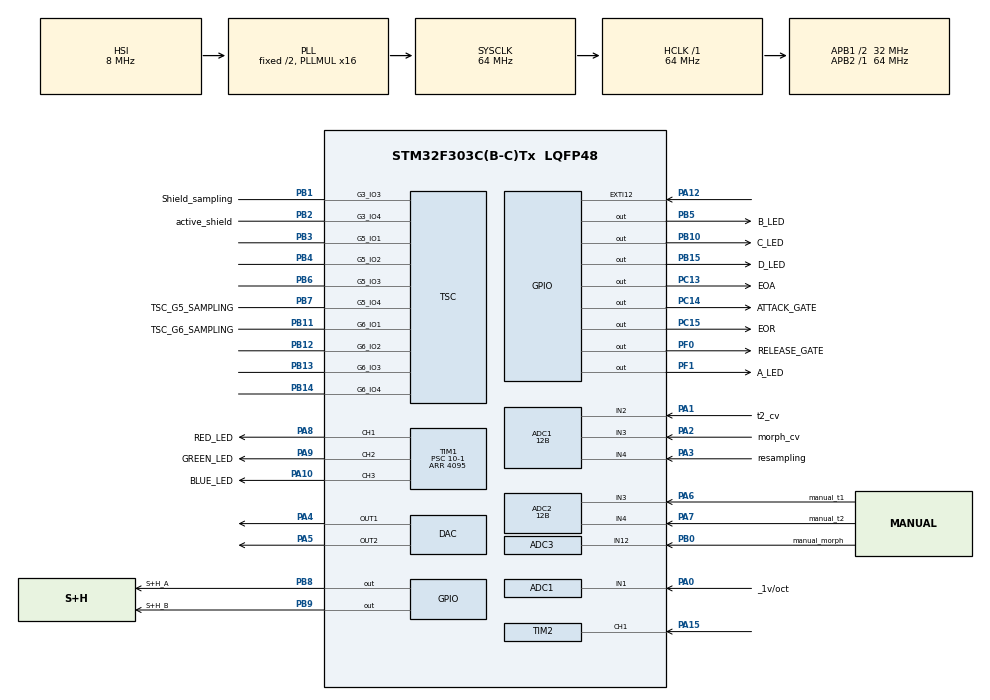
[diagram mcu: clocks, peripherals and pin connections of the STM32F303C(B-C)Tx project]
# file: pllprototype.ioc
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ADC1.Channel-0\#ChannelRegularConversion=ADC_CHANNEL_1
ADC1.Channel-1\#ChannelRegularConversion=ADC_CHANNEL_2
ADC1.Channel-2\#ChannelRegularConversion=ADC_CHANNEL_3
ADC1.Channel-4\#ChannelRegularConversion=ADC_CHANNEL_4
ADC1.ClockPrescaler=ADC_CLOCK_ASYNC_DIV1
ADC1.ContinuousConvMode=ENABLE
ADC1.DMAContinuousRequests=ENABLE
ADC1.DataAlign=ADC_DATAALIGN_RIGHT
ADC1.DiscontinuousConvMode=DISABLE
ADC1.EOCSelection=ADC_EOC_SEQ_CONV
ADC1.EnableAnalogWatchDog1=false
ADC1.EnableAnalogWatchDog2=false
ADC1.EnableAnalogWatchDog3=false
ADC1.EnableInjectedConversion=DISABLE
ADC1.EnableRegularConversion=ENABLE
ADC1.ExternalTrigConv=ADC_SOFTWARE_START
ADC1.ExternalTrigConvEdge=ADC_EXTERNALTRIGCONVEDGE_NONE
ADC1.LowPowerAutoWait=DISABLE
ADC1.NbrOfConversion=4
ADC1.NbrOfConversionFlag=1
ADC1.Offset-0\#ChannelRegularConversion=0
ADC1.Offset-1\#ChannelRegularConversion=0
ADC1.Offset-2\#ChannelRegularConversion=0
ADC1.Offset-4\#ChannelRegularConversion=0
ADC1.OffsetNumber-0\#ChannelRegularConversion=ADC_OFFSET_NONE
ADC1.OffsetNumber-1\#ChannelRegularConversion=ADC_OFFSET_NONE
ADC1.OffsetNumber-2\#ChannelRegularConversion=ADC_OFFSET_NONE
ADC1.OffsetNumber-4\#ChannelRegularConversion=ADC_OFFSET_NONE
ADC1.Overrun=ADC_OVR_DATA_OVERWRITTEN
ADC1.Rank-0\#ChannelRegularConversion=1
ADC1.Rank-1\#ChannelRegularConversion=2
ADC1.Rank-2\#ChannelRegularConversion=3
ADC1.Rank-4\#ChannelRegularConversion=4
ADC1.Resolution=ADC_RESOLUTION_12B
ADC1.SamplingTime-0\#ChannelRegularConversion=ADC_SAMPLETIME_181CYCLES_5
ADC1.SamplingTime-1\#ChannelRegularConversion=ADC_SAMPLETIME_181CYCLES_5
ADC1.SamplingTime-2\#ChannelRegularConversion=ADC_SAMPLETIME_181CYCLES_5
ADC1.SamplingTime-4\#ChannelRegularConversion=ADC_SAMPLETIME_181CYCLES_5
ADC1.ScanConvMode=ADC_SCAN_ENABLE
ADC1.master=1
ADC2.Channel-0\#ChannelRegularConversion=ADC_CHANNEL_3
ADC2.Channel-1\#ChannelRegularConversion=ADC_CHANNEL_4
ADC2.ClockPrescaler=ADC_CLOCK_ASYNC_DIV1
ADC2.ContinuousConvMode=ENABLE
ADC2.DMAContinuousRequests=ENABLE
ADC2.DataAlign=ADC_DATAALIGN_RIGHT
ADC2.DiscontinuousConvMode=DISABLE
ADC2.EOCSelection=ADC_EOC_SEQ_CONV
ADC2.EnableAnalogWatchDog1=false
ADC2.EnableAnalogWatchDog2=false
ADC2.EnableAnalogWatchDog3=false
ADC2.EnableInjectedConversion=ENABLE
ADC2.EnableRegularConversion=ENABLE
ADC2.ExternalTrigConv=ADC_SOFTWARE_START
ADC2.ExternalTrigConvEdge=ADC_EXTERNALTRIGCONVEDGE_NONE
ADC2.InjNumberOfConversion=0
ADC2.LowPowerAutoWait=DISABLE
ADC2.NbrOfConversion=2
ADC2.NbrOfConversionFlag=1
ADC2.Offset-0\#ChannelRegularConversion=0
ADC2.Offset-1\#ChannelRegularConversion=0
ADC2.OffsetNumber-0\#ChannelRegularConversion=ADC_OFFSET_NONE
ADC2.OffsetNumber-1\#ChannelRegularConversion=ADC_OFFSET_1
ADC2.Overrun=ADC_OVR_DATA_OVERWRITTEN
ADC2.Rank-0\#ChannelRegularConversion=1
ADC2.Rank-1\#ChannelRegularConversion=2
ADC2.Resolution=ADC_RESOLUTION_12B
ADC2.SamplingTime-0\#ChannelRegularConversion=ADC_SAMPLETIME_61CYCLES_5
ADC2.SamplingTime-1\#ChannelRegularConversion=ADC_SAMPLETIME_61CYCLES_5
ADC2.ScanConvMode=ADC_SCAN_ENABLE
ADC3.Channel-106\#ChannelRegularConversion=ADC_CHANNEL_12
ADC3.ClockPrescaler=ADC_CLOCK_ASYNC_DIV1
ADC3.ContinuousConvMode=ENABLE
ADC3.DMAContinuousRequests=ENABLE
ADC3.DataAlign=ADC_DATAALIGN_RIGHT
ADC3.DiscontinuousConvMode=DISABLE
ADC3.EOCSelection=ADC_EOC_SINGLE_CONV
ADC3.EnableAnalogWatchDog1=false
ADC3.EnableAnalogWatchDog2=false
ADC3.EnableAnalogWatchDog3=false
ADC3.EnableInjectedConversion=DISABLE
ADC3.EnableRegularConversion=ENABLE
ADC3.ExternalTrigConv=ADC_SOFTWARE_START
ADC3.ExternalTrigConvEdge=ADC_EXTERNALTRIGCONVEDGE_NONE
ADC3.LowPowerAutoWait=DISABLE
ADC3.NbrOfConversion=1
ADC3.NbrOfConversionFlag=1
ADC3.Offset-106\#ChannelRegularConversion=0
ADC3.OffsetNumber-106\#ChannelRegularConversion=ADC_OFFSET_NONE
ADC3.Overrun=ADC_OVR_DATA_OVERWRITTEN
ADC3.Rank-106\#ChannelRegularConversion=1
ADC3.Resolution=ADC_RESOLUTION_12B
ADC3.SamplingTime-106\#ChannelRegularConversion=ADC_SAMPLETIME_61CYCLES_5
ADC3.ScanConvMode=ADC_SCAN_DISABLE
ADC3.master=1
DAC.DAC_OutputBuffer=DAC_OUTPUTBUFFER_DISABLE
DAC.DAC_OutputBuffer2=DAC_OUTPUTBUFFER_DISABLE
DAC.DAC_Trigger=DAC_TRIGGER_T6_TRGO
DAC.DAC_Trigger2=DAC_TRIGGER_T6_TRGO
Dma.ADC1.0.Direction=DMA_PERIPH_TO_MEMORY
Dma.ADC1.0.Instance=DMA1_Channel1
Dma.ADC1.0.MemDataAlignment=DMA_MDATAALIGN_WORD
Dma.ADC1.0.MemInc=DMA_MINC_ENABLE
Dma.ADC1.0.Mode=DMA_CIRCULAR
Dma.ADC1.0.PeriphDataAlignment=DMA_PDATAALIGN_WORD
Dma.ADC1.0.PeriphInc=DMA_PINC_DISABLE
Dma.ADC1.0.Priority=DMA_PRIORITY_LOW
Dma.ADC2.1.Direction=DMA_PERIPH_TO_MEMORY
Dma.ADC2.1.Instance=DMA2_Channel1
Dma.ADC2.1.MemDataAlignment=DMA_MDATAALIGN_WORD
Dma.ADC2.1.MemInc=DMA_MINC_ENABLE
Dma.ADC2.1.Mode=DMA_CIRCULAR
Dma.ADC2.1.PeriphDataAlignment=DMA_PDATAALIGN_WORD
Dma.ADC2.1.PeriphInc=DMA_PINC_DISABLE
Dma.ADC2.1.Priority=DMA_PRIORITY_HIGH
Dma.ADC3.2.Direction=DMA_PERIPH_TO_MEMORY
Dma.ADC3.2.Instance=DMA2_Channel5
Dma.ADC3.2.MemDataAlignment=DMA_MDATAALIGN_WORD
Dma.ADC3.2.MemInc=DMA_MINC_ENABLE
Dma.ADC3.2.Mode=DMA_CIRCULAR
Dma.ADC3.2.PeriphDataAlignment=DMA_PDATAALIGN_WORD
Dma.ADC3.2.PeriphInc=DMA_PINC_DISABLE
Dma.ADC3.2.Priority=DMA_PRIORITY_HIGH
Dma.DAC_CH1.3.Direction=DMA_MEMORY_TO_PERIPH
Dma.DAC_CH1.3.Instance=DMA1_Channel3
Dma.DAC_CH1.3.MemDataAlignment=DMA_MDATAALIGN_HALFWORD
Dma.DAC_CH1.3.MemInc=DMA_MINC_ENABLE
Dma.DAC_CH1.3.Mode=DMA_CIRCULAR
Dma.DAC_CH1.3.PeriphDataAlignment=DMA_PDATAALIGN_HALFWORD
Dma.DAC_CH1.3.PeriphInc=DMA_PINC_DISABLE
Dma.DAC_CH1.3.Priority=DMA_PRIORITY_VERY_HIGH
Dma.DAC_CH2.4.Direction=DMA_MEMORY_TO_PERIPH
Dma.DAC_CH2.4.Instance=DMA1_Channel4
Dma.DAC_CH2.4.MemDataAlignment=DMA_MDATAALIGN_HALFWORD
Dma.DAC_CH2.4.MemInc=DMA_MINC_ENABLE
Dma.DAC_CH2.4.Mode=DMA_CIRCULAR
Dma.DAC_CH2.4.PeriphDataAlignment=DMA_PDATAALIGN_HALFWORD
Dma.DAC_CH2.4.PeriphInc=DMA_PINC_DISABLE
Dma.DAC_CH2.4.Priority=DMA_PRIORITY_VERY_HIGH
Dma.Request0=ADC1
Dma.Request1=ADC2
Dma.Request2=ADC3
Dma.Request3=DAC_CH1
Dma.Request4=DAC_CH2
Mcu.Family=STM32F3
Mcu.Name=STM32F303C(B-C)Tx
Mcu.Package=LQFP48
NVIC.DMA1_Channel1_IRQn=true\:2\:1\:true\:false\:true
NVIC.DMA1_Channel3_IRQn=true\:0\:0\:true\:false\:true
NVIC.DMA1_Channel4_IRQn=true\:0\:0\:true\:false\:true
NVIC.DMA2_Channel1_IRQn=true\:3\:0\:true\:false\:true
NVIC.DMA2_Channel5_IRQn=true\:2\:0\:true\:false\:true
NVIC.EXTI15_10_IRQn=true\:1\:0\:true\:false\:true
NVIC.PriorityGroup=NVIC_PRIORITYGROUP_2
NVIC.TIM2_IRQn=true\:0\:0\:false\:false\:true
NVIC.TIM6_DAC_IRQn=true\:0\:2\:false\:false\:true
NVIC.TIM7_IRQn=true\:0\:1\:false\:false\:true
NVIC.TIM8_UP_IRQn=true\:0\:1\:false\:false\:true
PA0.GPIO_Label=_1v/oct
PA0.Mode=IN1-Single-Ended
PA0.Signal=ADC1_IN1
PA1.GPIO_Label=t2_cv
PA1.Mode=IN2-Single-Ended
PA1.Signal=ADC1_IN2
PA10.GPIO_Label=BLUE_LED
PA10.Signal=S_TIM1_CH3
PA12.Signal=GPXTI12
PA13.Signal=SYS_JTMS-SWDIO
PA14.Signal=SYS_JTCK-SWCLK
PA15.Signal=S_TIM2_CH1_ETR
PA2.GPIO_Label=morph_cv
PA2.Mode=IN3-Single-Ended
PA2.Signal=ADC1_IN3
PA3.GPIO_Label=resampling
PA3.Mode=IN4-Single-Ended
PA3.Signal=ADC1_IN4
PA4.GPIO_Mode=GPIO_MODE_ANALOG
PA4.Signal=COMP_DAC1_group
PA5.Signal=COMP_DAC2_group
PA6.GPIO_Label=manual_t1
PA6.Mode=IN3-Single-Ended
PA6.Signal=ADC2_IN3
PA7.GPIO_Label=manual_t2
PA7.Mode=IN4-Single-Ended
PA7.Signal=ADC2_IN4
PA8.GPIO_Label=RED_LED
PA8.Signal=S_TIM1_CH1
PA9.GPIO_Label=GREEN_LED
PA9.Signal=S_TIM1_CH2
PB0.GPIO_Label=manual_morph
PB0.Mode=IN12-Single-Ended
PB0.Signal=ADC3_IN12
PB1.GPIO_Label=Shield_sampling
PB1.Mode=G3_IO3-Sampling
PB1.Signal=TSC_G3_IO3
PB10.GPIO_Label=C_LED
PB10.Signal=GPIO_Output
PB11.GPIO_Label=TSC_G6_SAMPLING
PB11.Mode=G6_IO1-Sampling
PB11.Signal=TSC_G6_IO1
PB12.Mode=G6_IO2-Channel
PB12.Signal=TSC_G6_IO2
PB13.Mode=G6_IO3-Channel
PB13.Signal=TSC_G6_IO3
PB14.Mode=G6_IO4-Channel
PB14.Signal=TSC_G6_IO4
PB15.GPIO_Label=D_LED
PB15.Signal=GPIO_Output
PB2.GPIO_Label=active_shield
PB2.Mode=G3_IO4-Shield
PB2.Signal=TSC_G3_IO4
PB3.Mode=G5_IO1-Channel
PB3.Signal=TSC_G5_IO1
PB4.Mode=G5_IO2-Channel
PB4.Signal=TSC_G5_IO2
PB5.GPIO_Label=B_LED
PB5.Signal=GPIO_Output
PB6.Mode=G5_IO3-Channel
PB6.Signal=TSC_G5_IO3
PB7.GPIO_Label=TSC_G5_SAMPLING
PB7.Mode=G5_IO4-Sampling
PB7.Signal=TSC_G5_IO4
PB8.GPIO_Label=S+H_A
PB8.Signal=GPIO_Output
PB9.GPIO_Label=S+H_B
PB9.Signal=GPIO_Output
PC13.GPIO_Label=EOA
PC13.Signal=GPIO_Output
PC14-OSC32_IN.GPIO_Label=ATTACK_GATE
PC14-OSC32_IN.Signal=GPIO_Output
PC15-OSC32_OUT.GPIO_Label=EOR
PC15-OSC32_OUT.Signal=GPIO_Output
PF0-OSC_IN.GPIO_Label=RELEASE_GATE
PF0-OSC_IN.Signal=GPIO_Output
PF1-OSC_OUT.GPIO_Label=A_LED
PF1-OSC_OUT.Signal=GPIO_Output
ProjectManager.HeapSize=0x200
ProjectManager.StackSize=0x400
ProjectManager.TargetToolchain=SW4STM32
RCC.ADC12PRES=RCC_ADC12PLLCLK_DIV16
RCC.ADC34PRES=RCC_ADC34PLLCLK_DIV16
RCC.AHBFreq_Value=64000000
RCC.APB1CLKDivider=RCC_HCLK_DIV2
RCC.APB1Freq_Value=32000000
RCC.APB1TimFreq_Value=64000000
RCC.APB2Freq_Value=64000000
RCC.APB2TimFreq_Value=64000000
RCC.CortexFreq_Value=64000000
RCC.HCLKFreq_Value=64000000
RCC.HSE_VALUE=8000000
RCC.HSI_VALUE=8000000
RCC.LSE_VALUE=32768
RCC.PLLMUL=RCC_PLL_MUL16
RCC.SYSCLKFreq_VALUE=64000000
RCC.SYSCLKSourceVirtual=RCC_SYSCLKSOURCE_PLLCLK
RCC.USBFreq_Value=64000000
SH.COMP_DAC1_group.0=DAC_OUT1,DAC_OUT1
SH.COMP_DAC2_group.0=DAC_OUT2,Enable_DAC_OUT2
SH.S_TIM1_CH1.0=TIM1_CH1,PWM Generation1 CH1
SH.S_TIM1_CH2.0=TIM1_CH2,PWM Generation2 CH2
SH.S_TIM1_CH3.0=TIM1_CH3,PWM Generation3 CH3
SH.S_TIM2_CH1_ETR.0=TIM2_CH1,Input_Capture1_from_TI1
TIM1.Channel-PWM\ Generation1\ CH1=TIM_CHANNEL_1
TIM1.Channel-PWM\ Generation2\ CH2=TIM_CHANNEL_2
TIM1.Channel-PWM\ Generation3\ CH3=TIM_CHANNEL_3
TIM1.Period=4095
TIM1.Prescaler=10-1
TIM2.Channel-Input_Capture1_from_TI1=TIM_CHANNEL_1
TIM2.ICPolarity_CH1=TIM_INPUTCHANNELPOLARITY_BOTHEDGE
TIM2.Period=4294967295
TIM2.Prescaler=1024
TIM4.Period=60000
TIM4.Prescaler=10000
TIM6.Period=1000
TIM6.Prescaler=1-1
TIM6.TIM_MasterOutputTrigger=TIM_TRGO_UPDATE
TIM7.Period=65535
TIM7.Prescaler=1-1
TIM8.Period=65535
TIM8.Prescaler=1-1
TIM8.RepetitionCounter=0
TIM8.TIM_MasterOutputTrigger=TIM_TRGO_UPDATE
TSC.CTPulseHighLength=TSC_CTPH_2CYCLES
TSC.CTPulseLowLength=TSC_CTPL_9CYCLES
TSC.ChannelIOs-G5_IO1=TSC_GROUP5_IO1
TSC.ChannelIOs-G5_IO2=TSC_GROUP5_IO2
TSC.ChannelIOs-G5_IO3=TSC_GROUP5_IO3
TSC.ChannelIOs-G6_IO2=TSC_GROUP6_IO2
TSC.ChannelIOs-G6_IO3=TSC_GROUP6_IO3
TSC.ChannelIOs-G6_IO4=TSC_GROUP6_IO4
TSC.MaxCountValue=TSC_MCV_16383
TSC.PulseGeneratorPrescaler=TSC_PG_PRESC_DIV32
TSC.SamplingIOs-G3_IO3=TSC_GROUP3_IO3
TSC.SamplingIOs-G5_IO4=TSC_GROUP5_IO4
TSC.SamplingIOs-G6_IO1=TSC_GROUP6_IO1
TSC.ShieldIOs-G3_IO4=TSC_GROUP3_IO4
VP_TIM3_VS_ClockSourceINT.Mode=Internal
VP_TIM4_VS_ClockSourceINT.Mode=Internal
VP_TIM6_VS_ClockSourceINT.Mode=Enable_Timer
VP_TIM7_VS_ClockSourceINT.Mode=Enable_Timer
VP_TIM8_VS_ClockSourceINT.Mode=Internal
board=pllprototype

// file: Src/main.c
/**
  ******************************************************************************
  * File Name          : main.c
  * Description        : Main program body
  ******************************************************************************
  ** This notice applies to any and all portions of this file
  * that are not between comment pairs USER CODE BEGIN and
  * USER CODE END. Other portions of this file, whether
  * inserted by the user or by software development tools
  * are owned by their respective copyright owners.
  *
  * COPYRIGHT(c) 2017 STMicroelectronics
  *
  * Redistribution and use in source and binary forms, with or without modification,
  * are permitted provided that the following conditions are met:
  *   1. Redistributions of source code must retain the above copyright notice,
  *      this list of conditions and the following disclaimer.
  *   2. Redistributions in binary form must reproduce the above copyright notice,
  *      this list of conditions and the following disclaimer in the documentation
  *      and/or other materials provided with the distribution.
  *   3. Neither the name of STMicroelectronics nor the names of its contributors
  *      may be used to endorse or promote products derived from this software
  *      without specific prior written permission.
  *
  * THIS SOFTWARE IS PROVIDED BY THE COPYRIGHT HOLDERS AND CONTRIBUTORS "AS IS"
  * AND ANY EXPRESS OR IMPLIED WARRANTIES, INCLUDING, BUT NOT LIMITED TO, THE
  * IMPLIED WARRANTIES OF MERCHANTABILITY AND FITNESS FOR A PARTICULAR PURPOSE ARE
  * DISCLAIMED. IN NO EVENT SHALL THE COPYRIGHT HOLDER OR CONTRIBUTORS BE LIABLE
  * FOR ANY DIRECT, INDIRECT, INCIDENTAL, SPECIAL, EXEMPLARY, OR CONSEQUENTIAL
  * DAMAGES (INCLUDING, BUT NOT LIMITED TO, PROCUREMENT OF SUBSTITUTE GOODS OR
  * SERVICES; LOSS OF USE, DATA, OR PROFITS; OR BUSINESS INTERRUPTION) HOWEVER
  * CAUSED AND ON ANY THEORY OF LIABILITY, WHETHER IN CONTRACT, STRICT LIABILITY,
  * OR TORT (INCLUDING NEGLIGENCE OR OTHERWISE) ARISING IN ANY WAY OUT OF THE USE
  * OF THIS SOFTWARE, EVEN IF ADVISED OF THE POSSIBILITY OF SUCH DAMAGE.
  *
  ******************************************************************************
  */
#include "main.h"
#include "stm32f3xx_hal.h"

/* USER CODE BEGIN Includes */

#include "tables.h"
#include "tsl_user.h"

/* USER CODE END Includes */

ADC_HandleTypeDef hadc1;
ADC_HandleTypeDef hadc2;
ADC_HandleTypeDef hadc3;
DMA_HandleTypeDef hdma_adc1;
DMA_HandleTypeDef hdma_adc2;
DMA_HandleTypeDef hdma_adc3;

DAC_HandleTypeDef hdac;
DMA_HandleTypeDef hdma_dac_ch1;
DMA_HandleTypeDef hdma_dac_ch2;

TIM_HandleTypeDef htim1;
TIM_HandleTypeDef htim2;
TIM_HandleTypeDef htim3;
TIM_HandleTypeDef htim4;
TIM_HandleTypeDef htim6;
TIM_HandleTypeDef htim7;
TIM_HandleTypeDef htim8;

TSC_HandleTypeDef htsc;

/* USER CODE BEGIN PV */
/* Private variables ---------------------------------------------------------*/
tsl_user_status_t tsl_status;

__IO uint32_t uhTSCAcquisitionValue1;
__IO uint32_t uhTSCAcquisitionValue2;
__IO uint32_t uhTSCAcquisitionValue3;
uint8_t not1;
uint8_t not2;
uint8_t not3;
uint8_t modeflag;
uint8_t modechanged;
uint8_t displayNewMode;
extern uint8_t morphBitShiftRight;
extern uint8_t morphBitShiftLeft;
extern uint8_t rowSelectBitShift;
extern uint8_t rowIndexBitShift;
uint8_t detectOn;
uint8_t rgbOn;
extern uint16_t dacbuffer1[1];
extern uint16_t dacbuffer2[1];
extern int span;
extern int spanx2;

Scale ratio1;
Scale row1;

Family moog1;
Family moog2;
Family triFudge;
Family triOdd;
Family triFold;
Family bounce;
Family sineFold;
Family perlin;
Family sawBend;
Family exciteBike;
Family rand;
Family gauss;
Family gauss_noconform;
Family gauss_low;
Family gauss_low_noconform;
Family algerian;
Family gammaSym;
Family gammaAsym;
Family sharpExpoSym;
Family sharpExpoAsym;
Family sharpLinSym;
Family sharpLinAsym;
Family quartSym;
Family quartAsym;
Family superEllipse1Sym;
Family superEllipse1Asym;
Family moogShifted;

const uint16_t sinefold_ctr_1[65] = {0,1755,3221,4645,6025,7357,8637,9863,11031,12137,13180,14156,15062,15896,16655,17337,17940,18463,18903,19259,19530,19715,19812,19822,19745,19579,19325,18984,18556,18042,17444,16762,15997,15259,14604,14034,13550,13154,12845,12624,12492,12448,12493,12624,12843,13148,13537,14009,14563,15197,15909,16696,17557,18488,19487,20551,21677,22863,24104,25398,26741,28130,29561,31030,32768};
const uint16_t sinefold_ctr_2[65] = {0,735,1259,1832,2482,3231,4097,5090,6218,7480,8869,10372,11969,13636,15341,17052,18730,20335,21825,23161,24303,25213,25859,26213,26252,25964,25339,24379,23093,21501,19628,17509,15187,12963,10988,9296,7917,6870,6166,5806,5785,6088,6693,7574,8696,10023,11515,13131,14828,16565,18303,20007,21645,23190,24621,25924,27091,28119,29012,29783,30447,31025,31543,32030,32768};
const uint16_t sinefold_ctr_3[65] = {0,1698,2972,4008,4759,5208,5364,5267,4983,4601,4226,3968,3938,4234,4933,6083,7697,9753,12185,14894,17747,20586,23240,25535,27307,28412,28742,28231,26863,24677,21768,18281,14409,10771,7722,5412,3942,3356,3639,4728,6512,8846,11561,14478,17418,20219,22740,24873,26549,27737,28448,28727,28651,28318,27841,27335,26911,26662,26663,26961,27572,28483,29656,31026,32768};
const uint16_t sinefold_ctr_4[65] = {0,827,1647,2786,4263,6018,7918,9775,11374,12512,13030,12844,11969,10523,8724,6864,5274,4281,4160,5092,7127,10171,13982,18193,22350,25964,28571,29796,29408,27353,23780,19032,13614,8672,4934,2756,2299,3514,6166,9871,14153,18505,22452,25608,27717,28670,28514,27428,25695,23655,21655,20007,18947,18612,19030,20124,21737,23660,25668,27557,29175,30442,31360,32006,32768};
const uint16_t sinefold_ctr_5[65] = {0,1576,2476,2878,2871,2694,2678,3159,4381,6420,9135,12181,15062,17239,18250,17829,15991,13057,9621,6444,4306,3841,5390,8900,13903,19579,24897,28810,30469,29407,25662,19805,12856,6767,2848,1696,3360,7368,12845,18710,23890,27526,29122,28610,26333,22945,19260,16080,14038,13488,14462,16696,19711,22937,25840,28032,29339,29815,29699,29340,29097,29247,29920,31077,32768};
const uint16_t sinefold_ctr_6[65] = {0,977,2212,3929,5831,7442,8290,8112,6998,5417,4099,3814,5096,8024,12132,16485,19931,21445,20475,17162,12380,7530,4166,3534,6163,11644,18681,25400,29868,30658,27309,20531,12068,5026,1515,2280,6858,13784,21058,26733,29449,28766,25218,20093,15011,11449,10339,11855,15433,20004,24346,27453,28799,28436,26914,25047,23638,23227,23960,25598,27651,29594,31059,31964,32768};
const uint16_t sinefold_ctr_7[65] = {0,1403,1889,1892,1985,2828,4785,7645,10624,12658,12901,11177,8184,5312,4112,5618,9820,15529,20752,23450,22400,17800,11328,5581,3088,5257,11703,20262,27730,31090,28747,21273,11321,3559,1087,4514,12206,21050,27721,29956,27333,21299,14479,9592,8413,11176,16624,22618,27044,28617,27287,24128,20787,18775,18889,20990,24192,27338,29519,30429,30392,30108,30246,31109,32768};
const uint16_t sinefold_ctr_8[65] = {0,1183,2787,4626,5846,5807,4645,3364,3333,5433,9376,13652,16226,15679,12144,7468,4397,5132,10028,17171,23183,24917,21207,13688,6178,2812,5853,14324,24276,30659,29922,21997,10574,2346,1533,8091,18364,27125,30263,26737,18873,10971,7023,8770,15021,22496,27632,28380,25071,20011,16123,15415,18087,22653,26917,29192,29085,27501,25944,25602,26747,28760,30686,31907,32768};
const uint16_t sinefold_ctr_9[65] = {0,1208,1408,1616,2871,5455,8387,9978,9130,6420,4019,4332,8189,13940,18250,18266,13738,7559,4126,6444,13876,22185,26075,22715,13903,5260,2754,8701,19910,29407,30828,22720,9847,1428,2848,12632,24214,30362,27737,18710,9474,5901,9905,18561,26333,28746,25082,18474,13573,13488,18015,24142,28274,28564,25840,22689,21546,23154,26386,29340,30779,30849,30655,31193,32768};

const uint16_t perlin6_1[65] = {0,506,1016,1530,2048,2571,3098,3630,4167,4710,5257,5809,6366,6928,7494,8065,8640,9220,9803,10389,10933,11475,12016,12554,13089,13621,14150,14676,15197,15715,16231,16744,17256,17766,18275,18781,19286,19789,20290,20789,21287,21783,22277,22770,23261,23750,24182,24615,25048,25482,25917,26354,26792,27232,27675,28119,28567,29017,29470,29926,30386,30850,31317,31788,32768};
const uint16_t perlin6_2[65] = {0,509,1030,1565,2116,2686,3276,3889,4524,5184,5869,6581,7318,8081,8870,9683,10520,11380,12259,13157,13870,14574,15268,15949,16614,17263,17893,18501,19087,19648,20197,20734,21260,21776,22280,22773,23255,23726,24187,24636,25075,25504,25921,26329,26726,27113,27263,27418,27580,27749,27928,28118,28320,28537,28770,29020,29288,29577,29887,30220,30576,30958,31366,31801,32768};
const uint16_t perlin6_3[65] = {0,637,1150,1548,1842,2049,2186,2275,2335,2390,2463,2576,2753,3013,3377,3863,4484,5252,6175,7256,8573,9949,11363,12796,14225,15624,16967,18225,19367,20374,21300,22158,22947,23670,24327,24920,25450,25919,26331,26687,26992,27249,27461,27633,27769,27874,27703,27559,27450,27383,27364,27399,27490,27640,27850,28120,28447,28827,29255,29724,30223,30741,31263,31774,32768};
const uint16_t perlin6_4[65] = {0,1104,2256,3414,4530,5550,6422,7101,7551,7753,7706,7435,6969,6171,5095,3860,2598,1447,539,0,442,1391,2821,4676,6872,9297,11811,14244,16402,18109,19518,20675,21586,22265,22729,23001,23109,23084,22963,22788,22606,22466,22427,22548,22894,23537,24453,25507,26569,27550,28392,29063,29553,29874,30049,30115,30113,30092,30097,30171,30346,30647,31079,31626,32768};
const uint16_t perlin6_5[65] = {0,499,902,1384,2080,3062,4289,5573,6561,7774,9487,11465,13433,15108,16235,16623,16181,14956,13166,10795,7881,5388,3857,3617,4786,7268,10755,14729,18458,21149,23030,24234,24826,24907,24614,24122,23639,23410,23718,24874,26758,28827,30689,32061,32768,32748,31582,30074,28532,27293,26472,25874,25616,25740,26216,26966,27871,28806,29654,30328,30774,31024,31290,31695,32768};
const uint16_t perlin6_6[65] = {0,788,1427,2217,3244,4395,5371,5701,4859,3531,2511,2335,3263,5117,7114,8212,10359,13034,15132,15838,14533,11966,8845,5193,2606,2214,4304,8321,12867,15992,17702,18286,18014,17297,16689,16888,18578,20974,22948,23838,23423,21917,19975,18425,17110,16425,16970,18312,20051,21630,22324,21970,21562,21703,22599,24151,26062,27964,29499,30411,30778,30879,31047,31515,32768};
const uint16_t perlin6_7[65] = {0,937,1522,2229,4238,7257,9498,9498,7319,5535,6018,7917,9727,9496,5678,2034,1274,3929,8008,10336,14681,17905,17712,14140,8920,3467,1989,5823,12719,17537,19360,19052,17779,17313,19715,23299,25128,24154,21193,18510,16540,16233,17764,20098,20845,18603,16927,17695,20985,25530,29335,30539,29242,27090,26102,24823,24498,25688,27786,29618,30428,30697,30966,31532,32768};
const uint16_t perlin6_8[65] = {0,732,1600,2059,1672,2325,5490,7424,6651,5814,9852,16521,17502,11423,7005,8782,11929,10370,2717,0,5062,10222,15607,19933,17642,10620,2893,3240,11926,18684,20047,18398,17675,21936,25633,24350,19955,16641,15944,18468,20719,17637,15180,17907,25024,31174,30392,25532,22472,19214,20437,25394,28710,28524,27257,27795,29755,30221,29518,29293,30185,30903,31182,31418,32768};
const uint16_t perlin6_9[65] = {0,891,1396,1274,1955,3741,4554,4824,5999,4396,3821,8798,9933,7145,10625,18843,15572,7019,8364,11363,5181,821,6172,10989,16882,15319,7315,2095,9076,16039,16248,14467,17988,21186,17975,13935,13044,15952,15240,12004,15182,22729,24628,19481,15160,12879,18936,23570,22479,21810,25200,25563,23796,24810,26072,25319,22196,22622,27131,30539,30446,29524,29958,31137,32768};

const uint16_t bounce1[65] = {0,543,1136,1766,2419,3082,3741,4384,4999,5575,6099,6564,6962,7284,7526,7684,7756,7741,7640,7455,7190,6852,6447,5984,5473,4923,4348,3759,3170,2594,2044,1536,1081,694,387,172,60,60,181,429,811,1329,1985,2780,3710,4773,5962,7269,8685,10197,11793,13457,15174,16925,18692,20455,22194,23888,25516,27058,28492,29799,30959,31954,32768};
const uint16_t bounce2[65] = {0,554,1157,1774,2369,2910,3371,3732,3980,4111,4130,4049,3891,3681,3454,3245,3090,3026,3086,3297,3680,4246,4999,5929,7018,8238,9549,10907,12259,13551,14725,15728,16509,17025,17241,17136,16701,15940,14874,13538,11981,10263,8456,6639,4896,3311,1967,940,297,91,361,1126,2388,4127,6303,8857,11710,14772,17936,21091,24121,26908,29343,31325,32768};
const uint16_t bounce3[65] = {0,570,1185,1769,2260,2611,2800,2833,2742,2581,2419,2334,2400,2677,3203,3988,5009,6212,7511,8803,9970,10897,11482,11650,11360,10616,9469,8013,6382,4738,3256,2112,1458,1416,2055,3386,5360,7859,10715,13714,16619,19185,21187,22436,22803,22230,20740,18440,15514,12208,8816,5651,3020,1196,393,745,2287,4956,8585,12917,17625,22337,26667,30249,32768};
const uint16_t bounce4[65] = {0,589,1204,1721,2054,2173,2109,1953,1831,1878,2204,2869,3861,5093,6408,7610,8492,8883,8678,7873,6568,4969,3352,2031,1299,1377,2374,4252,6828,9788,12727,15217,16867,17393,16673,14772,11949,8624,5323,2599,947,721,2075,4922,8941,13610,18284,22283,24999,25997,25081,22347,18169,13160,8088,3758,898,36,1418,4957,10233,16548,23018,28709,32768};
const uint16_t bounce5[65] = {0,610,1212,1629,1777,1698,1539,1510,1805,2529,3647,4976,6225,7068,7246,6649,5376,3731,2164,1166,1137,2272,4482,7394,10413,12861,14137,13881,12086,9124,5685,2630,792,763,2738,6436,11142,15851,19496,21205,20517,17524,12871,7638,3097,418,390,3204,8390,14889,21288,26132,28273,27153,22961,16619,9592,3563,45,16,3670,10343,18637,26726,32768};
const uint16_t bounce6[65] = {0,631,1204,1500,1485,1331,1336,1768,2722,4037,5330,6131,6082,5114,3524,1914,994,1319,3052,5850,8934,11323,12178,11121,8419,4952,1954,603,1603,4891,9605,14320,17506,18052,15680,11098,5815,1677,250,2265,7325,13973,20134,23790,23666,19705,13143,6157,1165,24,3378,10382,18931,26309,30085,28937,23146,14559,6030,501,16,5004,14080,24443,32768};
const uint16_t bounce7[65] = {0,651,1184,1353,1236,1184,1590,2606,3982,5145,5489,4736,3170,1583,939,1882,4349,7496,10016,10732,9201,6018,2639,777,1593,5094,10021,14330,16091,14408,9917,4608,995,987,4959,11476,17842,21263,20125,14810,7630,1874,363,4129,11855,20357,25945,26076,20564,11773,3655,31,2850,11231,21744,29860,31954,26977,17029,6526,295,1412,9754,21947,32768};
const uint16_t bounce8[65] = {0,650,1114,1164,1040,1255,2141,3492,4601,4719,3638,1980,928,1510,3857,6959,9141,9061,6615,3175,910,1520,5127,10027,13555,13618,10029,4785,1051,1344,5968,12666,17778,18333,13859,6837,1413,1042,6408,14852,21751,23140,18074,9351,2053,680,6482,16570,25418,27974,22636,12337,3027,325,6230,17813,28726,32768,27499,15799,4383,44,5702,18583,31630};
const uint16_t bounce9[65] = {0,640,1024,974,937,1514,2762,3963,4150,3015,1392,780,2174,5098,7715,8103,5800,2406,609,2218,6638,11042,12296,9328,4155,657,1810,7364,13754,16501,13490,6726,1145,1151,7317,15703,20484,18130,10149,2271,471,6597,16789,24013,23047,14395,4197,10,5355,16969,26879,28009,19372,7038,9,3792,16260,28903,32768,24934,10853,694,2141,14740,29954};

const uint16_t trifold_1[65] = {0,512,1024,1536,2048,2560,3072,3584,4096,4608,5120,5632,6144,6656,7168,7680,8192,8704,9216,9728,10240,10752,11264,11776,12288,12800,13312,13824,14336,14848,15360,15872,16384,16896,17408,17920,18432,18944,19456,19968,20480,20992,21504,22016,22528,23040,23552,24064,24576,25088,25600,26112,26624,27136,27648,28160,28672,29184,29696,30208,30720,31232,31744,32256,32768};
const uint16_t trifold_2[65] = {32768,31232,29696,28160,26624,25088,23552,22016,20480,18944,17408,15872,14336,12800,11264,9728,8192,6656,5120,3584,2048,512,0,1536,3072,4608,6144,7680,9216,10752,12288,13824,15360,16896,18432,19968,21504,23040,24576,26112,27648,29184,30720,32256,31744,30208,28672,27136,25600,24064,22528,20992,19456,17920,16384,14848,13312,11776,10240,8704,7168,5632,4096,2560,1024};
const uint16_t trifold_3[65] = {16384,18432,20480,22528,24576,26624,28672,30720,32768,31232,29184,27136,25088,23040,20992,18944,16896,14848,12800,10752,8704,6656,4608,2560,512,1024,3072,5120,7168,9216,11264,13312,15360,17408,19456,21504,23552,25600,27648,29696,31744,32256,30208,28160,26112,24064,22016,19968,17920,15872,13824,11776,9728,7680,5632,3584,1536,0,2048,4096,6144,8192,10240,12288,14336};
const uint16_t trifold_4[65] = {0,2521,5041,7562,10082,12603,15124,17644,20165,22686,25206,27727,30247,32768,30247,27727,25206,22686,20165,17644,15124,12603,10082,7562,5041,2521,0,2521,5041,7562,10082,12603,15124,17644,20165,22686,25206,27727,30247,32768,30247,27727,25206,22686,20165,17644,15124,12603,10082,7562,5041,2521,0,2521,5041,7562,10082,12603,15124,17644,20165,22686,25206,27727,30247};
const uint16_t trifold_5[65] = {16384,13312,10240,7168,4096,1024,1536,4608,7680,10752,13824,16896,19968,23040,26112,29184,32256,30720,27648,24576,21504,18432,15360,12288,9216,6144,3072,0,2560,5632,8704,11776,14848,17920,20992,24064,27136,30208,32768,29696,26624,23552,20480,17408,14336,11264,8192,5120,2048,512,3584,6656,9728,12800,15872,18944,22016,25088,28160,31232,31744,28672,25600,22528,19456};
const uint16_t trifold_6[65] = {32768,29184,25600,22016,18432,14848,11264,7680,4096,512,2048,5632,9216,12800,16384,19968,23552,27136,30720,31232,27648,24064,20480,16896,13312,9728,6144,2560,0,3584,7168,10752,14336,17920,21504,25088,28672,32256,29696,26112,22528,18944,15360,11776,8192,4608,1024,1536,5120,8704,12288,15872,19456,23040,26624,30208,31744,28160,24576,20992,17408,13824,10240,6656,3072};
const uint16_t trifold_7[65] = {16384,20480,24576,28672,32768,29184,25088,20992,16896,12800,8704,4608,512,3072,7168,11264,15360,19456,23552,27648,31744,30208,26112,22016,17920,13824,9728,5632,1536,2048,6144,10240,14336,18432,22528,26624,30720,31232,27136,23040,18944,14848,10752,6656,2560,1024,5120,9216,13312,17408,21504,25600,29696,32256,28160,24064,19968,15872,11776,7680,3584,0,4096,8192,12288};
const uint16_t trifold_8[65] = {0,4608,9216,13824,18432,23040,27648,32256,29696,25088,20480,15872,11264,6656,2048,2560,7168,11776,16384,20992,25600,30208,31744,27136,22528,17920,13312,8704,4096,512,5120,9728,14336,18944,23552,28160,32768,29184,24576,19968,15360,10752,6144,1536,3072,7680,12288,16896,21504,26112,30720,31232,26624,22016,17408,12800,8192,3584,1024,5632,10240,14848,19456,24064,28672};
const uint16_t trifold_9[65] = {16384,10923,5461,0,2731,8192,13653,19115,24576,30037,32768,27307,21845,16384,10923,5461,0,2731,8192,13653,19115,24576,30037,32768,27307,21845,16384,10923,5461,0,2731,8192,13653,19115,24576,30037,32768,27307,21845,16384,10923,5461,0,2731,8192,13653,19115,24576,30037,32768,27307,21845,16384,10923,5461,0,2731,8192,13653,19115,24576,30037,32768,27307,21845};

const uint16_t triodd_1[65] = {0,512,1024,1536,2048,2560,3072,3584,4096,4608,5120,5632,6144,6656,7168,7680,8192,8704,9216,9728,10240,10752,11264,11776,12288,12800,13312,13824,14336,14848,15360,15872,16384,16896,17408,17920,18432,18944,19456,19968,20480,20992,21504,22016,22528,23040,23552,24064,24576,25088,25600,26112,26624,27136,27648,28160,28672,29184,29696,30208,30720,31232,31744,32256,32768};
const uint16_t triodd_2[65] = {1024,2560,4096,5632,7168,8704,10240,11776,13312,14848,16384,17920,19456,20992,22528,24064,25600,27136,28672,30208,31744,32256,30720,29184,27648,26112,24576,23040,21504,19968,18432,16896,15360,13824,12288,10752,9216,7680,6144,4608,3072,1536,0,512,2048,3584,5120,6656,8192,9728,11264,12800,14336,15872,17408,18944,20480,22016,23552,25088,26624,28160,29696,31232,32768};
const uint16_t triodd_3[65] = {0,2521,5041,7562,10082,12603,15124,17644,20165,22686,25206,27727,30247,32768,30247,27727,25206,22686,20165,17644,15124,12603,10082,7562,5041,2521,0,2521,5041,7562,10082,12603,15124,17644,20165,22686,25206,27727,30247,32768,30247,27727,25206,22686,20165,17644,15124,12603,10082,7562,5041,2521,0,2521,5041,7562,10082,12603,15124,17644,20165,22686,25206,27727,30247};
const uint16_t triodd_4[65] = {3072,6656,10240,13824,17408,20992,24576,28160,31744,30208,26624,23040,19456,15872,12288,8704,5120,1536,1024,4608,8192,11776,15360,18944,22528,26112,29696,32256,28672,25088,21504,17920,14336,10752,7168,3584,0,2560,6144,9728,13312,16896,20480,24064,27648,31232,30720,27136,23552,19968,16384,12800,9216,5632,2048,512,4096,7680,11264,14848,18432,22016,25600,29184,32768};
const uint16_t triodd_5[65] = {0,4608,9216,13824,18432,23040,27648,32256,29696,25088,20480,15872,11264,6656,2048,2560,7168,11776,16384,20992,25600,30208,31744,27136,22528,17920,13312,8704,4096,512,5120,9728,14336,18944,23552,28160,32768,29184,24576,19968,15360,10752,6144,1536,3072,7680,12288,16896,21504,26112,30720,31232,26624,22016,17408,12800,8192,3584,1024,5632,10240,14848,19456,24064,28672};
const uint16_t triodd_6[65] = {5120,10752,16384,22016,27648,32256,26624,20992,15360,9728,4096,512,6144,11776,17408,23040,28672,31232,25600,19968,14336,8704,3072,1536,7168,12800,18432,24064,29696,30208,24576,18944,13312,7680,2048,2560,8192,13824,19456,25088,30720,29184,23552,17920,12288,6656,1024,3584,9216,14848,20480,26112,31744,28160,22528,16896,11264,5632,0,4608,10240,15872,21504,27136,32768};
const uint16_t triodd_7[65] = {0,6554,13107,19661,26214,32768,26214,19661,13107,6554,0,6554,13107,19661,26214,32768,26214,19661,13107,6554,0,6554,13107,19661,26214,32768,26214,19661,13107,6554,0,6554,13107,19661,26214,32768,26214,19661,13107,6554,0,6554,13107,19661,26214,32768,26214,19661,13107,6554,0,6554,13107,19661,26214,32768,26214,19661,13107,6554,0,6554,13107,19661,26214};
const uint16_t triodd_8[65] = {7562,15124,22686,30247,27727,20165,12603,5041,2521,10082,17644,25206,32768,25206,17644,10082,2521,5041,12603,20165,27727,30247,22686,15124,7562,0,7562,15124,22686,30247,27727,20165,12603,5041,2521,10082,17644,25206,32768,25206,17644,10082,2521,5041,12603,20165,27727,30247,22686,15124,7562,0,7562,15124,22686,30247,27727,20165,12603,5041,2521,10082,17644,25206,32768};
const uint16_t triodd_9[65] = {0,8704,17408,26112,31744,23040,14336,5632,3072,11776,20480,29184,28672,19968,11264,2560,6144,14848,23552,32256,25600,16896,8192,512,9216,17920,26624,31232,22528,13824,5120,3584,12288,20992,29696,28160,19456,10752,2048,6656,15360,24064,32768,25088,16384,7680,1024,9728,18432,27136,30720,22016,13312,4608,4096,12800,21504,30208,27648,18944,10240,1536,7168,15872,24576};

const uint16_t trifudge_1[65] = {256,752,1248,1744,2240,2736,3232,3728,4224,4720,5216,5712,6208,6704,7200,7696,8192,8704,9216,9728,10240,10752,11264,11776,12288,12800,13312,13824,14336,14848,15360,15872,16384,16896,17408,17920,18432,18944,19456,19968,20480,20992,21504,22016,22528,23040,23552,24064,24576,25104,25632,26160,26688,27216,27744,28272,28800,29328,29856,30384,30912,31440,31968,32496,32512};
const uint16_t trifudge_2[65] = {0,1632,3328,5088,6912,8800,10752,12768,14848,16992,19200,21472,23808,26208,28672,31200,32256,31232,30208,29184,28160,27136,26112,25088,24064,23040,22016,20992,19968,18944,17920,16896,15872,14848,13824,12800,11776,10752,9728,8704,7680,6656,5632,4608,3584,2560,1536,512,0,2528,4992,7392,9728,12000,14208,16352,18432,20448,22400,24288,26112,27872,29568,31200,32768};
const uint16_t trifudge_3[65] = {1024,2560,4096,5632,7168,8704,10240,11776,13312,14848,16384,17920,19456,20992,22528,24064,25600,27136,28672,30208,31744,32256,30720,29184,27648,26112,24576,23040,21504,19968,18432,16896,15360,13824,12288,10752,9216,7680,6144,4608,3072,1536,0,512,2048,3584,5120,6656,8192,9728,11264,12800,14336,15872,17408,18944,20480,22016,23552,25088,26624,28160,29696,31232,32768};
const uint16_t trifudge_4[65] = {0,3072,6583,10533,14921,19749,25015,30720,32768,31232,29184,27136,25088,23040,20992,18944,16896,14848,12800,10752,8704,6656,4608,2560,512,1024,3072,5120,7168,9216,11264,13312,15360,17408,19456,21504,23552,25600,27648,29696,31744,32256,30208,28160,26112,24064,22016,19968,17920,15872,13824,11776,9728,7680,5632,3584,1536,0,5998,11557,16677,21358,25600,29403,32768};
const uint16_t trifudge_5[65] = {0,2521,5041,7562,10082,12603,15124,17644,20165,22686,25206,27727,30247,32768,30247,27727,25206,22686,20165,17644,15124,12603,10082,7562,5041,2521,0,2521,5041,7562,10082,12603,15124,17644,20165,22686,25206,27727,30247,32768,30247,27727,25206,22686,20165,17644,15124,12603,10082,7562,5041,2521,0,2521,5041,7562,10082,12603,15124,17644,20165,22686,25206,27727,30247};
const uint16_t trifudge_6[65] = {0,6016,13312,21888,31744,31232,28160,25088,22016,18944,15872,12800,9728,6656,3584,512,2048,5120,8192,11264,14336,17408,20480,23552,26624,29696,32768,30208,27136,24064,20992,17920,14848,11776,8704,5632,2560,0,3072,6144,9216,12288,15360,18432,21504,24576,27648,30720,32256,29184,26112,23040,19968,16896,13824,10752,7680,4608,1536,1024,4096,13184,20992,27520,32768};
const uint16_t trifudge_7[65] = {3072,6656,10240,13824,17408,20992,24576,28160,31744,30208,26624,23040,19456,15872,12288,8704,5120,1536,1024,4608,8192,11776,15360,18944,22528,26112,29696,32256,28672,25088,21504,17920,14336,10752,7168,3584,0,2560,6144,9728,13312,16896,20480,24064,27648,31232,30720,27136,23552,19968,16384,12800,9216,5632,2048,512,4096,7680,11264,14848,18432,22016,25600,29184,32768};
const uint16_t trifudge_8[65] = {0,7168,16725,28672,32768,29184,25088,20992,16896,12800,8704,4608,512,3072,7168,11264,15360,19456,23552,27648,31744,30208,26112,22016,17920,13824,9728,5632,1536,2048,6144,10240,14336,18432,22528,26624,30720,31232,27136,23040,18944,14848,10752,6656,2560,1024,5120,9216,13312,17408,21504,25600,29696,32256,28160,24064,19968,15872,11776,7680,3584,0,13312,24235,32768};
const uint16_t trifudge_9[65] = {0,4608,9216,13824,18432,23040,27648,32256,29696,25088,20480,15872,11264,6656,2048,2560,7168,11776,16384,20992,25600,30208,31744,27136,22528,17920,13312,8704,4096,512,5120,9728,14336,18944,23552,28160,32768,29184,24576,19968,15360,10752,6144,1536,3072,7680,12288,16896,21504,26112,30720,31232,26624,22016,17408,12800,8192,3584,1024,5632,10240,14848,19456,24064,28672};

const uint16_t moog1attack[65] = { 21659 ,  21503 ,  20634 ,  18818 ,  16219 ,  13251 ,  10408 ,   8124 , 6692 ,   6231 ,   6690 ,   7878 ,   9512 ,  11283 ,12902 ,  14146 , 14884 ,  15086 ,  14809 ,  14180 ,  13364 ,  12531 ,  11830 ,  11367 , 11196 ,  11315 ,  11676 ,  12202 ,  12798 ,  13372 ,  13850 ,  14183 , 14352 ,  14367 ,  14262 ,  14084 ,  13886 ,  13715 ,  13609 ,  13588 , 13658 ,  13807 ,  14014 ,  14251 ,  14490 ,  14705 ,  14880 ,  15005 , 15082 ,  15119 ,  15129 ,  15128 ,  15131 ,  15151 ,  15195 ,  15267 , 15365 ,  15483 ,  15612 ,  15745 ,  15872 ,  15988 ,  16090 ,  16177 , 16251 };
const uint16_t moog1release[65] = { 21602 ,  21529 ,  21444 ,  21360 ,  21275 ,  21190 ,  21105 ,  21020 , 20934 ,  20849 ,  20764 ,  20679 ,  20594 ,  20509 ,  20424 ,  20340 , 20256 ,  20172 ,  20087 ,  20003 ,  19918 ,  19833 ,  19747 ,  19661 , 19575 ,  19488 ,  19403 ,  19317 ,  19233 ,  19149 ,  19066 ,  18983 , 18901 ,  18818 ,  18735 ,  18650 ,  18564 ,  18477 ,  18388 ,  18299 , 18210 ,  18121 ,  18034 ,  17950 ,  17868 ,  17788 ,  17710 ,  17633 , 17556 ,  17477 ,  17394 ,  17307 ,  17216 ,  17120 ,  17022 ,  16922 , 16825 ,  16731 ,  16645 ,  16566 ,  16496 ,  16433 ,  16374 ,  16315 , 16251 };
const uint16_t moog2attack[65] = { 21503 ,  21557 ,  21528 ,  21343 ,  20945 ,  20305 ,  19421 ,  18318 , 17038 ,  15636 ,  14173 ,  12714 ,  11320 ,  10046 ,   8940 ,   8037 , 7366 ,   6939 ,   6760 ,   6822 ,   7107 ,   7591 ,   8243 ,   9025 , 9899 ,  10825 ,  11764 ,  12680 ,  13539 ,  14313 ,  14979 ,  15522 , 15931 ,  16203 ,  16340 ,  16350 ,  16246 ,  16045 ,  15764 ,  15426 , 15053 ,  14667 ,  14287 ,  13934 ,  13623 ,  13368 ,  13179 ,  13062 , 13021 ,  13055 ,  13161 ,  13332 ,  13559 ,  13834 ,  14144 ,  14477 , 14821 ,  15165 ,  15497 ,  15808 ,  16090 ,  16338 ,  16546 ,  16713 , 16839 };
const uint16_t moog2release[65] = { 21455 ,  21377 ,  21295 ,  21209 ,  21120 ,  21026 ,  20929 ,  20829 , 20725 ,  20619 ,  20510 ,  20401 ,  20293 ,  20185 ,  20080 ,  19978 , 19881 ,  19789 ,  19704 ,  19625 ,  19553 ,  19489 ,  19430 ,  19378 , 19331 ,  19287 ,  19246 ,  19204 ,  19162 ,  19115 ,  19063 ,  19003 , 18933 ,  18853 ,  18761 ,  18656 ,  18538 ,  18408 ,  18267 ,  18117 , 17959 ,  17796 ,  17632 ,  17470 ,  17313 ,  17166 ,  17031 ,  16913 , 16813 ,  16735 ,  16680 ,  16647 ,  16637 ,  16648 ,  16677 ,  16721 , 16775 ,  16834 ,  16891 ,  16940 ,  16974 ,  16987 ,  16972 ,  16924 , 16839 };
const uint16_t moog3attack[65] = { 21000 ,  21133 ,  21247 ,  21318 ,  21324 ,  21244 ,  21061 ,  20767 , 20358 ,  19836 ,  19207 ,  18482 ,  17675 ,  16804 ,  15885 ,  14937 , 13981 ,  13035 ,  12116 ,  11244 ,  10431 ,   9694 ,   9042 ,   8486 , 8034 ,   7689 ,   7454 ,   7331 ,   7317 ,   7409 ,   7601 ,   7887 , 8257 ,   8703 ,   9213 ,   9776 ,  10381 ,  11015 ,  11667 ,  12326 , 12979 ,  13617 ,  14229 ,  14808 ,  15346 ,  15835 ,  16272 ,  16651 , 16971 ,  17229 ,  17426 ,  17563 ,  17642 ,  17665 ,  17637 ,  17562 , 17446 ,  17295 ,  17114 ,  16911 ,  16692 ,  16464 ,  16232 ,  16004 , 15784 };
const uint16_t moog3release[65] = { 20885 ,  20751 ,  20621 ,  20496 ,  20376 ,  20264 ,  20158 ,  20062 , 19975 ,  19897 ,  19829 ,  19772 ,  19725 ,  19688 ,  19661 ,  19643 , 19633 ,  19631 ,  19634 ,  19641 ,  19652 ,  19663 ,  19674 ,  19682 , 19685 ,  19682 ,  19670 ,  19647 ,  19612 ,  19563 ,  19499 ,  19417 , 19318 ,  19201 ,  19065 ,  18911 ,  18738 ,  18547 ,  18341 ,  18119 , 17885 ,  17640 ,  17388 ,  17130 ,  16870 ,  16612 ,  16359 ,  16115 , 15883 ,  15667 ,  15470 ,  15296 ,  15148 ,  15027 ,  14937 ,  14879 , 14855 ,  14864 ,  14907 ,  14983 ,  15091 ,  15228 ,  15392 ,  15578 , 15784 };
const uint16_t moog5attack[65] = { 21901 ,  21982 ,  22047 ,  22087 ,  22093 ,  22057 ,  21970 ,  21826 , 21619 ,  21347 ,  21009 ,  20606 ,  20140 ,  19614 ,  19035 ,  18407 , 17739 ,  17038 ,  16312 ,  15569 ,  14819 ,  14069 ,  13328 ,  12604 , 11905 ,  11238 ,  10610 ,  10027 ,   9494 ,   9015 ,   8596 ,   8238 , 7945 ,   7718 ,   7557 ,   7463 ,   7435 ,   7473 ,   7573 ,   7734 , 7952 ,   8223 ,   8544 ,   8911 ,   9318 ,   9760 ,  10233 ,  10731 , 11249 ,  11781 ,  12322 ,  12866 ,  13410 ,  13947 ,  14473 ,  14984 , 15477 ,  15946 ,  16390 ,  16805 ,  17188 ,  17539 ,  17854 ,  18134 , 18377 };
const uint16_t moog5release[65] = { 21874 ,  21772 ,  21659 ,  21535 ,  21400 ,  21253 ,  21096 ,  20928 , 20750 ,  20563 ,  20367 ,  20164 ,  19954 ,  19738 ,  19518 ,  19294 , 19070 ,  18845 ,  18622 ,  18401 ,  18186 ,  17976 ,  17775 ,  17583 , 17403 ,  17235 ,  17081 ,  16943 ,  16821 ,  16716 ,  16631 ,  16565 , 16518 ,  16492 ,  16486 ,  16501 ,  16535 ,  16589 ,  16662 ,  16753 , 16860 ,  16982 ,  17117 ,  17263 ,  17419 ,  17582 ,  17749 ,  17917 , 18085 ,  18250 ,  18407 ,  18555 ,  18690 ,  18809 ,  18910 ,  18990 , 19046 ,  19075 ,  19075 ,  19045 ,  18982 ,  18885 ,  18752 ,  18583 , 18377 };
const uint16_t moog6attack[65] = { 19268 ,  19400 ,  19537 ,  19676 ,  19810 ,  19933 ,  20041 ,  20127 , 20187 ,  20217 ,  20213 ,  20172 ,  20093 ,  19974 ,  19816 ,  19617 , 19380 ,  19105 ,  18795 ,  18452 ,  18078 ,  17677 ,  17253 ,  16808 , 16347 ,  15873 ,  15390 ,  14902 ,  14414 ,  13928 ,  13448 ,  12978 , 12522 ,  12082 ,  11662 ,  11265 ,  10893 ,  10549 ,  10234 ,   9950 , 9700 ,   9484 ,   9303 ,   9159 ,   9051 ,   8980 ,   8946 ,   8948 , 8986 ,   9059 ,   9167 ,   9307 ,   9479 ,   9681 ,   9912 ,  10168 , 10449 ,  10753 ,  11077 ,  11418 ,  11775 ,  12146 ,  12527 ,  12917 , 13313 };
const uint16_t moog6release[65] = { 19223 ,  19117 ,  19020 ,  18934 ,  18858 ,  18793 ,  18739 ,  18696 , 18664 ,  18644 ,  18634 ,  18636 ,  18648 ,  18671 ,  18703 ,  18745 , 18795 ,  18854 ,  18920 ,  18992 ,  19070 ,  19152 ,  19238 ,  19326 , 19416 ,  19505 ,  19594 ,  19680 ,  19762 ,  19840 ,  19911 ,  19974 , 20028 ,  20072 ,  20105 ,  20125 ,  20132 ,  20123 ,  20099 ,  20057 , 19999 ,  19921 ,  19825 ,  19709 ,  19574 ,  19418 ,  19241 ,  19045 , 18828 ,  18591 ,  18335 ,  18060 ,  17768 ,  17457 ,  17131 ,  16790 , 16435 ,  16068 ,  15691 ,  15305 ,  14912 ,  14514 ,  14114 ,  13712 , 13313 };
const uint16_t moog7attack[65] = { 20353 ,  20310 ,  20270 ,  20231 ,  20193 ,  20151 ,  20103 ,  20048 , 19982 ,  19903 ,  19810 ,  19700 ,  19572 ,  19425 ,  19258 ,  19072 , 18865 ,  18639 ,  18393 ,  18129 ,  17848 ,  17549 ,  17236 ,  16910 , 16571 ,  16223 ,  15866 ,  15503 ,  15135 ,  14765 ,  14395 ,  14026 , 13661 ,  13301 ,  12949 ,  12606 ,  12273 ,  11954 ,  11648 ,  11358 , 11085 ,  10830 ,  10595 ,  10380 ,  10186 ,  10014 ,   9866 ,   9740 , 9638 ,   9560 ,   9506 ,   9477 ,   9472 ,   9490 ,   9532 ,   9598 , 9686 ,   9797 ,   9929 ,  10081 ,  10254 ,  10446 ,  10655 ,  10881 , 11123 };
const uint16_t moog7release[65] = { 20321 ,  20362 ,  20407 ,  20455 ,  20505 ,  20557 ,  20609 ,  20662 , 20715 ,  20766 ,  20816 ,  20864 ,  20908 ,  20949 ,  20985 ,  21015 , 21040 ,  21058 ,  21069 ,  21072 ,  21066 ,  21050 ,  21025 ,  20990 , 20943 ,  20885 ,  20816 ,  20734 ,  20639 ,  20532 ,  20412 ,  20278 , 20131 ,  19971 ,  19797 ,  19610 ,  19410 ,  19197 ,  18972 ,  18734 , 18484 ,  18223 ,  17951 ,  17669 ,  17378 ,  17078 ,  16770 ,  16456 , 16135 ,  15809 ,  15480 ,  15147 ,  14813 ,  14478 ,  14144 ,  13812 , 13484 ,  13159 ,  12841 ,  12529 ,  12226 ,  11933 ,  11651 ,  11380 , 11123 };
const uint16_t moog8attack[65] = { 22736 ,  22717 ,  22692 ,  22659 ,  22617 ,  22566 ,  22504 ,  22430 , 22343 ,  22241 ,  22122 ,  21988 ,  21835 ,  21665 ,  21476 ,  21268 , 21042 ,  20797 ,  20534 ,  20253 ,  19955 ,  19640 ,  19311 ,  18967 , 18609 ,  18240 ,  17861 ,  17472 ,  17075 ,  16672 ,  16265 ,  15855 , 15443 ,  15031 ,  14620 ,  14213 ,  13811 ,  13415 ,  13027 ,  12647 , 12278 ,  11921 ,  11577 ,  11248 ,  10933 ,  10635 ,  10355 ,  10093 , 9849 ,   9626 ,   9423 ,   9241 ,   9080 ,   8942 ,   8825 ,   8731 , 8660 ,   8611 ,   8585 ,   8581 ,   8599 ,   8640 ,   8702 ,   8786 , 8890 };
const uint16_t moog8release[65] = { 22767 ,  22790 ,  22806 ,  22815 ,  22815 ,  22807 ,  22790 ,  22763 , 22726 ,  22679 ,  22621 ,  22552 ,  22471 ,  22379 ,  22275 ,  22158 , 22030 ,  21889 ,  21736 ,  21570 ,  21392 ,  21201 ,  20998 ,  20783 , 20555 ,  20316 ,  20066 ,  19804 ,  19532 ,  19250 ,  18957 ,  18656 , 18346 ,  18027 ,  17701 ,  17369 ,  17030 ,  16687 ,  16339 ,  15987 , 15633 ,  15277 ,  14920 ,  14563 ,  14208 ,  13855 ,  13504 ,  13158 , 12817 ,  12483 ,  12156 ,  11837 ,  11527 ,  11228 ,  10940 ,  10665 , 10402 ,  10155 ,   9922 ,   9705 ,   9505 ,   9323 ,   9160 ,   9015 , 8890 };
const uint16_t moog9attack[65] = { 23211 ,  23356 ,  23491 ,  23614 ,  23725 ,  23824 ,  23909 ,  23979 , 24033 ,  24070 ,  24088 ,  24088 ,  24069 ,  24029 ,  23968 ,  23885 , 23782 ,  23656 ,  23509 ,  23341 ,  23151 ,  22940 ,  22709 ,  22458 , 22187 ,  21898 ,  21592 ,  21269 ,  20930 ,  20577 ,  20210 ,  19831 , 19441 ,  19041 ,  18632 ,  18217 ,  17795 ,  17369 ,  16940 ,  16508 , 16077 ,  15646 ,  15217 ,  14791 ,  14371 ,  13955 ,  13547 ,  13148 , 12757 ,  12377 ,  12008 ,  11652 ,  11309 ,  10981 ,  10667 ,  10370 , 10089 ,   9825 ,   9579 ,   9352 ,   9143 ,   8954 ,   8784 ,   8635 , 8505 };
const uint16_t moog9release[65] = { 23600 ,  23429 ,  23246 ,  23052 ,  22846 ,  22629 ,  22401 ,  22163 , 21913 ,  21654 ,  21384 ,  21104 ,  20815 ,  20517 ,  20211 ,  19896 , 19573 ,  19243 ,  18906 ,  18563 ,  18215 ,  17861 ,  17503 ,  17142 , 16778 ,  16411 ,  16043 ,  15674 ,  15305 ,  14937 ,  14571 ,  14207 , 13846 ,  13489 ,  13137 ,  12791 ,  12451 ,  12119 ,  11794 ,  11479 , 11174 ,  10879 ,  10595 ,  10324 ,  10066 ,   9821 ,   9591 ,   9375 , 9176 ,   8993 ,   8826 ,   8677 ,   8546 ,   8434 ,   8340 ,   8266 , 8211 ,   8176 ,   8162 ,   8167 ,   8194 ,   8241 ,   8308 ,   8397 , 8505 };

const uint16_t moog9attack2[65] = { 13722 ,  12707 ,  10958 ,  12036 ,  12302 ,  11953 ,  12138 ,  12307 , 12301 ,  12374 ,  12473 ,  12535 ,  12604 ,  12682 ,  12754 ,  12825 , 12899 ,  12972 ,  13044 ,  13117 ,  13190 ,  13262 ,  13335 ,  13408 , 13481 ,  13553 ,  13626 ,  13699 ,  13772 ,  13844 ,  13917 ,  13990 , 14063 ,  14136 ,  14208 ,  14281 ,  14354 ,  14427 ,  14499 ,  14572 , 14645 ,  14718 ,  14790 ,  14863 ,  14936 ,  15009 ,  15081 ,  15154 , 15227 ,  15300 ,  15373 ,  15445 ,  15518 ,  15591 ,  15664 ,  15736 , 15809 ,  15882 ,  15955 ,  16027 ,  16100 ,  16173 ,  16246 ,  16318 , 16391  };
const uint16_t moog9release2[65] = { 13674 ,  20975 ,  20903 ,  20830 ,  20757 ,  20684 ,  20612 ,  20539 , 20466 ,  20393 ,  20320 ,  20248 ,  20175 ,  20102 ,  20029 ,  19957 , 19884 ,  19811 ,  19738 ,  19666 ,  19593 ,  19520 ,  19447 ,  19375 , 19302 ,  19229 ,  19156 ,  19083 ,  19011 ,  18938 ,  18865 ,  18792 , 18720 ,  18647 ,  18574 ,  18501 ,  18429 ,  18356 ,  18283 ,  18210 , 18138 ,  18065 ,  17992 ,  17919 ,  17847 ,  17774 ,  17701 ,  17628 , 17555 ,  17483 ,  17410 ,  17337 ,  17264 ,  17192 ,  17119 ,  17046 , 16973 ,  16901 ,  16828 ,  16755 ,  16682 ,  16610 ,  16537 ,  16464 , 16391  };
const uint16_t moog8attack2[65] = { 17119 ,   8161 ,  14448 ,  10228 ,  13085 ,  11480 ,  12468 ,  12119 , 12317 ,  12425 ,  12389 ,  12592 ,  12542 ,  12717 ,  12711 ,  12841 , 12875 ,  12972 ,  13030 ,  13111 ,  13180 ,  13254 ,  13327 ,  13399 , 13473 ,  13544 ,  13618 ,  13690 ,  13763 ,  13836 ,  13909 ,  13981 , 14054 ,  14127 ,  14200 ,  14273 ,  14345 ,  14418 ,  14491 ,  14564 , 14636 ,  14709 ,  14782 ,  14855 ,  14927 ,  15000 ,  15073 ,  15146 , 15218 ,  15291 ,  15364 ,  15437 ,  15510 ,  15582 ,  15655 ,  15728 , 15801 ,  15873 ,  15946 ,  16019 ,  16092 ,  16164 ,  16237 ,  16310 , 16383  };
const uint16_t moog8release2[65] = { 17071 ,  20967 ,  20894 ,  20821 ,  20749 ,  20676 ,  20603 ,  20530 , 20457 ,  20385 ,  20312 ,  20239 ,  20166 ,  20094 ,  20021 ,  19948 , 19875 ,  19803 ,  19730 ,  19657 ,  19584 ,  19512 ,  19439 ,  19366 , 19293 ,  19221 ,  19148 ,  19075 ,  19002 ,  18929 ,  18857 ,  18784 , 18711 ,  18638 ,  18566 ,  18493 ,  18420 ,  18347 ,  18275 ,  18202 , 18129 ,  18056 ,  17984 ,  17911 ,  17838 ,  17765 ,  17692 ,  17620 , 17547 ,  17474 ,  17401 ,  17329 ,  17256 ,  17183 ,  17110 ,  17038 , 16965 ,  16892 ,  16819 ,  16747 ,  16674 ,  16601 ,  16528 ,  16455 , 16383  };
const uint16_t moog7attack2[65] = { 19553 ,   9783 ,   8656 ,  14934 ,  12325 ,  10044 ,  13074 ,  12968 , 11312 ,  12450 ,  13003 ,  12152 ,  12438 ,  12964 ,  12655 ,  12659 , 13006 ,  12969 ,  12933 ,  13133 ,  13203 ,  13199 ,  13316 ,  13412 , 13444 ,  13525 ,  13618 ,  13675 ,  13744 ,  13829 ,  13897 ,  13965 , 14043 ,  14116 ,  14185 ,  14260 ,  14334 ,  14405 ,  14478 ,  14551 , 14623 ,  14696 ,  14769 ,  14842 ,  14914 ,  14987 ,  15060 ,  15133 , 15206 ,  15279 ,  15351 ,  15424 ,  15497 ,  15570 ,  15642 ,  15715 , 15788 ,  15861 ,  15933 ,  16006 ,  16079 ,  16152 ,  16224 ,  16297 , 16370  };
const uint16_t moog7release2[65] = { 19505 ,  20954 ,  20881 ,  20809 ,  20736 ,  20663 ,  20590 ,  20517 , 20445 ,  20372 ,  20299 ,  20226 ,  20154 ,  20081 ,  20008 ,  19935 , 19863 ,  19790 ,  19717 ,  19644 ,  19572 ,  19499 ,  19426 ,  19353 , 19280 ,  19208 ,  19135 ,  19062 ,  18989 ,  18917 ,  18844 ,  18771 , 18698 ,  18626 ,  18553 ,  18480 ,  18407 ,  18335 ,  18262 ,  18189 , 18116 ,  18044 ,  17971 ,  17898 ,  17825 ,  17752 ,  17680 ,  17607 , 17534 ,  17461 ,  17389 ,  17316 ,  17243 ,  17170 ,  17098 ,  17025 , 16952 ,  16879 ,  16807 ,  16734 ,  16661 ,  16588 ,  16515 ,  16443 , 16370  };
const uint16_t moog6attack2[65] = { 20585 ,  15420 ,   8051 ,   7469 ,  12607 ,  15579 ,  13361 ,  10237 , 10443 ,  12900 ,  14015 ,  12856 ,  11584 ,  11908 ,  13076 ,  13490 , 12931 ,  12454 ,  12723 ,  13288 ,  13454 ,  13214 ,  13070 ,  13266 , 13555 ,  13642 ,  13564 ,  13555 ,  13698 ,  13863 ,  13930 ,  13932 , 13976 ,  14086 ,  14197 ,  14262 ,  14302 ,  14366 ,  14457 ,  14546 , 14612 ,  14671 ,  14741 ,  14823 ,  14902 ,  14971 ,  15038 ,  15110 , 15187 ,  15262 ,  15333 ,  15403 ,  15476 ,  15551 ,  15625 ,  15696 , 15768 ,  15841 ,  15915 ,  15988 ,  16060 ,  16132 ,  16205 ,  16278 , 16351  };
const uint16_t moog6release2[65] = { 20537 ,  20935 ,  20862 ,  20789 ,  20717 ,  20644 ,  20571 ,  20498 , 20426 ,  20353 ,  20280 ,  20207 ,  20135 ,  20062 ,  19989 ,  19916 , 19843 ,  19771 ,  19698 ,  19625 ,  19552 ,  19480 ,  19407 ,  19334 , 19261 ,  19189 ,  19116 ,  19043 ,  18970 ,  18898 ,  18825 ,  18752 , 18679 ,  18606 ,  18534 ,  18461 ,  18388 ,  18315 ,  18243 ,  18170 , 18097 ,  18024 ,  17952 ,  17879 ,  17806 ,  17733 ,  17661 ,  17588 , 17515 ,  17442 ,  17370 ,  17297 ,  17224 ,  17151 ,  17078 ,  17006 , 16933 ,  16860 ,  16787 ,  16715 ,  16642 ,  16569 ,  16496 ,  16424 , 16351  };
const uint16_t moog5attack2[65] = { 20901 ,  19021 ,  14108 ,   8861 ,   6550 ,   8110 ,  11858 ,  15053 , 15828 ,  14206 ,  11719 ,  10150 ,  10361 ,  11920 ,  13630 ,  14427 , 14029 ,  12964 ,  12079 ,  11944 ,  12547 ,  13409 ,  13984 ,  14008 , 13619 ,  13188 ,  13041 ,  13263 ,  13687 ,  14054 ,  14188 ,  14095 , 13924 ,  13844 ,  13934 ,  14150 ,  14378 ,  14517 ,  14543 ,  14506 , 14489 ,  14544 ,  14668 ,  14816 ,  14936 ,  15003 ,  15031 ,  15056 , 15109 ,  15196 ,  15303 ,  15403 ,  15481 ,  15538 ,  15587 ,  15646 , 15721 ,  15807 ,  15895 ,  15973 ,  16042 ,  16104 ,  16168 ,  16239 , 16317  };
const uint16_t moog5release2[65] = { 20853 ,  20906 ,  20833 ,  20761 ,  20688 ,  20615 ,  20542 ,  20470 , 20397 ,  20324 ,  20251 ,  20179 ,  20106 ,  20033 ,  19960 ,  19887 , 19815 ,  19742 ,  19669 ,  19596 ,  19524 ,  19451 ,  19378 ,  19305 , 19233 ,  19160 ,  19087 ,  19014 ,  18941 ,  18869 ,  18796 ,  18723 , 18651 ,  18578 ,  18505 ,  18432 ,  18359 ,  18286 ,  18214 ,  18142 , 18069 ,  17996 ,  17922 ,  17849 ,  17777 ,  17705 ,  17633 ,  17560 , 17487 ,  17413 ,  17339 ,  17266 ,  17194 ,  17124 ,  17053 ,  16980 , 16904 ,  16828 ,  16754 ,  16683 ,  16615 ,  16546 ,  16474 ,  16397 , 16317  };
const uint16_t moog4attack2[65] = { 20953 ,  20437 ,  18473 ,  15119 ,  11316 ,   8217 ,   6671 ,   6960 , 8775 ,  11391 ,  13935 ,  15674 ,  16213 ,  15571 ,  14120 ,  12427 , 11054 ,  10395 ,  10575 ,  11450 ,  12686 ,  13885 ,  14714 ,  14993 , 14734 ,  14108 ,  13374 ,  12790 ,  12532 ,  12658 ,  13100 ,  13705 , 14291 ,  14707 ,  14871 ,  14790 ,  14542 ,  14247 ,  14020 ,  13944 , 14043 ,  14286 ,  14602 ,  14909 ,  15137 ,  15250 ,  15252 ,  15177 , 15082 ,  15019 ,  15024 ,  15110 ,  15261 ,  15445 ,  15625 ,  15768 , 15858 ,  15898 ,  15903 ,  15899 ,  15910 ,  15953 ,  16032 ,  16140 , 16264  };
const uint16_t moog4release2[65] = { 20904 ,  20862 ,  20790 ,  20717 ,  20645 ,  20573 ,  20501 ,  20428 , 20354 ,  20281 ,  20207 ,  20133 ,  20061 ,  19988 ,  19917 ,  19845 , 19774 ,  19702 ,  19629 ,  19555 ,  19480 ,  19405 ,  19331 ,  19258 , 19186 ,  19116 ,  19046 ,  18977 ,  18905 ,  18832 ,  18756 ,  18679 , 18601 ,  18525 ,  18452 ,  18382 ,  18315 ,  18249 ,  18183 ,  18113 , 18039 ,  17960 ,  17877 ,  17793 ,  17713 ,  17639 ,  17572 ,  17512 , 17456 ,  17397 ,  17331 ,  17255 ,  17168 ,  17073 ,  16977 ,  16887 , 16812 ,  16753 ,  16708 ,  16670 ,  16628 ,  16571 ,  16490 ,  16386 , 16264  };
const uint16_t moog3attack2[65] = { 20908 ,  20833 ,  20267 ,  18982 ,  17007 ,  14574 ,  12023 ,   9711 , 7942 ,   6922 ,   6736 ,   7344 ,   8600 ,  10282 ,  12126 ,  13873 , 15297 ,  16241 ,  16626 ,  16461 ,  15828 ,  14867 ,  13752 ,  12662 , 11757 ,  11156 ,  10924 ,  11071 ,  11552 ,  12281 ,  13142 ,  14015 , 14788 ,  15371 ,  15712 ,  15795 ,  15642 ,  15306 ,  14859 ,  14386 , 13963 ,  13655 ,  13505 ,  13529 ,  13719 ,  14042 ,  14453 ,  14896 , 15316 ,  15668 ,  15919 ,  16053 ,  16073 ,  15995 ,  15850 ,  15675 , 15506 ,  15376 ,  15311 ,  15323 ,  15414 ,  15574 ,  15784 ,  16022 , 16262  };
const uint16_t moog3release2[65] = { 20852 ,  20780 ,  20704 ,  20630 ,  20559 ,  20493 ,  20428 ,  20366 , 20304 ,  20241 ,  20175 ,  20105 ,  20030 ,  19950 ,  19865 ,  19777 , 19688 ,  19601 ,  19517 ,  19438 ,  19367 ,  19304 ,  19247 ,  19196 , 19147 ,  19097 ,  19042 ,  18980 ,  18907 ,  18824 ,  18729 ,  18627 , 18519 ,  18412 ,  18310 ,  18218 ,  18141 ,  18081 ,  18036 ,  18005 , 17983 ,  17962 ,  17935 ,  17894 ,  17833 ,  17749 ,  17639 ,  17509 , 17364 ,  17214 ,  17070 ,  16944 ,  16846 ,  16782 ,  16755 ,  16761 , 16791 ,  16832 ,  16868 ,  16882 ,  16857 ,  16784 ,  16657 ,  16480 , 16262  };
const uint16_t moog2attack2[65] = { 20947 ,  20955 ,  20820 ,  20435 ,  19732 ,  18698 ,  17369 ,  15817 , 14141 ,  12447 ,  10843 ,   9427 ,   8282 ,   7467 ,   7017 ,   6945 , 7235 ,   7853 ,   8743 ,   9837 ,  11059 ,  12328 ,  13564 ,  14698 , 15667 ,  16426 ,  16944 ,  17208 ,  17221 ,  17002 ,  16584 ,  16011 , 15332 ,  14602 ,  13874 ,  13199 ,  12622 ,  12176 ,  11887 ,  11768 , 11821 ,  12036 ,  12395 ,  12870 ,  13429 ,  14036 ,  14655 ,  15249 , 15789 ,  16246 ,  16603 ,  16848 ,  16976 ,  16991 ,  16904 ,  16731 , 16493 ,  16213 ,  15917 ,  15629 ,  15370 ,  15161 ,  15016 ,  14944 , 14951  };
const uint16_t moog2release2[65] = { 20920 ,  20863 ,  20794 ,  20714 ,  20623 ,  20521 ,  20410 ,  20292 , 20168 ,  20044 ,  19920 ,  19802 ,  19693 ,  19595 ,  19512 ,  19443 , 19392 ,  19356 ,  19335 ,  19327 ,  19326 ,  19330 ,  19334 ,  19331 , 19318 ,  19289 ,  19240 ,  19169 ,  19074 ,  18954 ,  18812 ,  18651 , 18475 ,  18290 ,  18104 ,  17923 ,  17755 ,  17609 ,  17489 ,  17402 , 17349 ,  17332 ,  17350 ,  17399 ,  17472 ,  17562 ,  17657 ,  17749 , 17824 ,  17873 ,  17885 ,  17852 ,  17769 ,  17632 ,  17443 ,  17206 , 16930 ,  16624 ,  16304 ,  15984 ,  15681 ,  15412 ,  15193 ,  15036 , 14951  };
const uint16_t moog1attack2[65] = { 20345 ,  20343 ,  20322 ,  20245 ,  20079 ,  19798 ,  19386 ,  18837 , 18157 ,  17358 ,  16460 ,  15489 ,  14471 ,  13438 ,  12418 ,  11443 , 10538 ,   9729 ,   9037 ,   8478 ,   8065 ,   7806 ,   7704 ,   7757 , 7960 ,   8302 ,   8771 ,   9350 ,  10020 ,  10760 ,  11548 ,  12362 , 13180 ,  13980 ,  14742 ,  15449 ,  16085 ,  16636 ,  17092 ,  17447 , 17696 ,  17839 ,  17879 ,  17820 ,  17670 ,  17440 ,  17141 ,  16787 , 16392 ,  15971 ,  15540 ,  15113 ,  14704 ,  14326 ,  13991 ,  13708 , 13486 ,  13331 ,  13245 ,  13232 ,  13289 ,  13415 ,  13606 ,  13855 , 14155  };
const uint16_t moog1release2[65] = { 20381 ,  20395 ,  20418 ,  20447 ,  20479 ,  20511 ,  20540 ,  20564 , 20578 ,  20581 ,  20569 ,  20539 ,  20490 ,  20421 ,  20330 ,  20216 , 20081 ,  19924 ,  19748 ,  19555 ,  19348 ,  19130 ,  18904 ,  18676 , 18449 ,  18228 ,  18018 ,  17824 ,  17649 ,  17498 ,  17374 ,  17280 , 17217 ,  17186 ,  17189 ,  17223 ,  17287 ,  17379 ,  17495 ,  17629 , 17778 ,  17934 ,  18091 ,  18243 ,  18382 ,  18503 ,  18597 ,  18660 , 18685 ,  18669 ,  18607 ,  18498 ,  18341 ,  18135 ,  17883 ,  17588 , 17255 ,  16890 ,  16500 ,  16094 ,  15681 ,  15270 ,  14872 ,  14497 , 14155  };

const uint16_t two_step[65] = {0,164,645,1415,2427,3621,4926,6263,7551,8715,9683,10398,10818,10923,10923,10923,10923,10923,10923,10923,10923,10923,10923,10923,10923,10923,10949,11242,11843,12716,13809,15057,16384,17711,18958,20051,20925,21526,21819,21845,21845,21845,21845,21845,21845,21845,21845,21845,21845,21845,21845,21845,21950,22369,23085,24053,25217,26505,27842,29146,30341,31353,32123,32604,32768};
const uint16_t two_step_plateau[65] = {0,0,0,0,0,0,0,0,0,0,0,0,0,10,353,1165,2399,3980,5814,7790,9790,11695,13389,14772,15760,16295,16384,16384,16384,16384,16384,16384,16384,16384,16384,16384,16384,16384,16384,16473,17008,17996,19379,21073,22978,24978,26954,28788,30369,31603,32415,32758,32768,32768,32768,32768,32768,32768,32768,32768,32768,32768,32768,32768,32768};
const uint16_t three_step[65] = {0,239,930,1990,3297,4697,6027,7131,7880,8187,8192,8192,8192,8192,8192,8192,8192,8192,8192,8315,8882,9848,11099,12489,13855,15039,15900,16340,16384,16384,16384,16384,16384,16384,16384,16384,16384,16428,16868,17729,18913,20279,21669,22920,23886,24453,24576,24576,24576,24576,24576,24576,24576,24576,24576,24581,24888,25637,26741,28071,29471,30778,31838,32529,32768};
const uint16_t three_step_plateau[65] = {0,0,0,0,0,0,0,0,312,1345,2907,4697,6372,7609,8172,8192,8192,8192,8192,8192,8192,8192,8368,9253,10721,12489,14219,15578,16305,16384,16384,16384,16384,16384,16384,16384,16463,17190,18549,20279,22047,23515,24400,24576,24576,24576,24576,24576,24576,24576,24596,25159,26396,28071,29861,31423,32456,32768,32768,32768,32768,32768,32768,32768,32768};
const uint16_t four_step[65] = {0,315,1198,2481,3916,5229,6167,6550,6554,6554,6554,6554,6554,6554,6554,6745,7513,8726,10152,11515,12555,13072,13107,13107,13107,13107,13107,13107,13107,13205,13851,14983,16384,17785,18917,19563,19661,19661,19661,19661,19661,19661,19661,19696,20213,21253,22616,24042,25255,26023,26214,26214,26214,26214,26214,26214,26214,26218,26601,27539,28852,30287,31570,32453,32768};
const uint16_t four_step_plateau[65] = {0,0,0,0,0,0,16,645,2023,3758,5356,6362,6554,6554,6554,6554,6554,6554,6695,7630,9191,10934,12363,13072,13107,13107,13107,13107,13107,13107,13494,14699,16384,18069,19274,19661,19661,19661,19661,19661,19661,19696,20405,21834,23577,25138,26073,26214,26214,26214,26214,26214,26214,26406,27412,29010,30745,32123,32752,32768,32768,32768,32768,32768,32768};
const uint16_t five_step[65] = {0,388,1443,2865,4248,5199,5461,5461,5461,5461,5461,5461,5514,6169,7399,8855,10123,10841,10923,10923,10923,10923,10923,10923,11131,12027,13386,14821,15924,16381,16384,16384,16384,16384,16384,16387,16844,17947,19382,20741,21637,21845,21845,21845,21845,21845,21845,21927,22644,23908,25362,26590,27243,27296,27296,27296,27296,27296,27296,27558,28512,29898,31322,32379,32768};
const uint16_t five_step_plateau[65] = {0,0,0,0,0,3,620,2067,3776,5073,5461,5461,5461,5461,5461,5491,6261,7791,9479,10660,10923,10923,10923,10923,10923,11005,11921,13519,15170,16224,16384,16384,16384,16384,16384,16544,17598,19249,20847,21763,21845,21845,21845,21845,21845,22107,23286,24970,26498,27266,27296,27299,27302,27305,27307,27695,28992,30701,32148,32765,32768,32768,32768,32768,32768};

const uint16_t fivept_sawbend_pre[5] = {0,10813,16384,21627,32768};
const uint16_t fivept_sawbend_second[5] = {0,24576,16384,8192,32768};
const uint16_t fivept_sawbend_third[5] = {0,21627,16384,10813,32768};
const uint16_t fivept_sawbend_fourth[5] = {0,26214,16384,6554,32768};
const uint16_t fivept_sawbend_fifth[5] = {0,32768,16384,0,32768};

const uint16_t excitebike1[9] = {0,16384,16384,32768,16384,16384,0,16384,32768};
const uint16_t excitebike2[9] = {0,0,16384,32768,16384,0,16384,32768,32768};
const uint16_t excitebike3[9] = {0,32768,16384,0,16384,32768,16384,0,32768};
const uint16_t excitebike4[9] = {0,10912,21843,32768,21845,10923,0,16384,32768};
const uint16_t excitebike5[9] = {0,21843,21843,32768,10922,10923,0,21823,32768};
const uint16_t excitebike6[9] = {0,16384,16384,10813,10813,24576,24576,21823,32768};
const uint16_t excitebike7[9] = {0,26214,6554,24576,8192,21627,10813,21955,32768};
const uint16_t excitebike8[9] = {0,18350,13107,21299,29491,13435,25559,20316,32768};
const uint16_t excitebike9[9] = {0,13107,13107,19661,26214,13107,13107,22938,32768};

// conforming, with otherwise random distribution of values

const uint16_t rand32[9] = {0,1493,9928,295,24535,10417,28796,10518,32768};
const uint16_t rand31[9] = {0,22857,16065,14102,16997,22115,5129,31427,32768};
const uint16_t rand30[9] = {0,7731,12805,17639,29403,27034,16561,8420,32768};
const uint16_t rand29[9] = {0,29691,14159,22083,11535,12766,18763,16833,32768};
const uint16_t rand28[9] = {0,27627,20652,133,10516,22268,8889,3523,32768};
const uint16_t rand27[9] = {0,12239,3116,5575,26,9119,25263,14209,32768};
const uint16_t rand26[9] = {0,15692,19073,30977,8964,3348,18797,25470,32768};
const uint16_t rand25[9] = {0,21090,22064,31653,10852,27094,22948,17322,32768};
const uint16_t rand24[9] = {0,27565,31968,2599,18411,2265,22983,23235,32768};
const uint16_t rand23[9] = {0,12642,13518,32505,18229,4969,14453,30121,32768};
const uint16_t rand22[9] = {0,17637,6487,32496,22873,15642,21667,16807,32768};
const uint16_t rand21[9] = {0,2131,31784,14508,29894,28373,9826,7715,32768};
const uint16_t rand20[9] = {0,11846,19607,1159,15756,8109,6877,2689,32768};
const uint16_t rand19[9] = {0,18725,11414,17908,12882,19396,3229,28304,32768};
const uint16_t rand18[9] = {0,27481,15895,24679,20925,28474,22059,12831,32768};
const uint16_t rand17[9] = {0,21221,19357,9554,13411,24713,31287,1820,32768};
const uint16_t rand16[9] = {0,15605,26494,31126,17348,13258,32484,27582,32768};
const uint16_t rand15[9] = {0,7176,16461,19822,29926,16865,15778,22007,32768};
const uint16_t rand14[9] = {0,30349,29059,30605,13528,12642,6929,23989,32768};
const uint16_t rand13[9] = {0,13137,29823,28006,26707,9234,18833,8357,32768};
const uint16_t rand12[9] = {0,31370,16253,2414,23284,17215,14270,27559,32768};
const uint16_t rand11[9] = {0,29804,18615,9750,22615,14391,21557,2970,32768};
const uint16_t rand10[9] = {0,12654,1268,12860,13043,24974,9055,20666,32768};
const uint16_t rand9[9] = {0,24079,30391,3283,6162,28788,15976,2238,32768};
const uint16_t rand8[9] = {0,23974,11982,7385,1682,15239,14296,15544,32768};
const uint16_t rand7[9] = {0,22634,9076,15554,18962,27668,32334,14728,32768};
const uint16_t rand6[9] = {0,30352,19172,18175,11822,11115,102,19468,32768};
const uint16_t rand5[9] = {0,5944,18625,15316,22884,11756,18715,11303,32768};
const uint16_t rand4[9] = {0,27091,26434,29608,9363,16315,12260,20538,32768};
const uint16_t rand3[9] = {0,27215,27741,21409,16903,6534,28248,19447,32768};
const uint16_t rand2[9] = {0,22192,8852,11568,19026,4554,1833,20813,32768};
const uint16_t rand1[9] = {0,11151,22417,27851,28455,30586,16587,25338,32768};
const uint16_t rand0[9] = {0,4386,399,27875,31776,29667,2523,19933,32768};

//conforming, with gaussian distribution centered at .5, standard deviation progresses from 0 to .9

const uint16_t gauss32[9] = {0,4856,15794,16207,19423,22985,11060,20072,32768};
const uint16_t gauss31[9] = {0,12792,13218,8247,32768,21286,18827,529,32768};
const uint16_t gauss30[9] = {0,24240,11829,21355,2575,0,22100,26298,32768};
const uint16_t gauss29[9] = {0,15295,32768,24868,4794,0,0,4853,32768};
const uint16_t gauss28[9] = {0,27480,24389,23811,14757,13005,26726,19225,32768};
const uint16_t gauss27[9] = {0,13869,13666,19341,17123,21086,18300,6241,32768};
const uint16_t gauss26[9] = {0,19043,32037,21181,13314,10755,25954,32768,32768};
const uint16_t gauss25[9] = {0,32768,5711,29557,8809,7314,17688,18814,32768};
const uint16_t gauss24[9] = {0,15578,12830,1704,20451,22529,7638,5921,32768};
const uint16_t gauss23[9] = {0,18392,20164,16760,17322,22983,19332,12337,32768};
const uint16_t gauss22[9] = {0,20476,2129,32768,18481,9845,9471,16375,32768};
const uint16_t gauss21[9] = {0,11687,19124,17372,27525,22739,20930,19144,32768};
const uint16_t gauss20[9] = {0,21545,13979,16198,6131,19222,14924,15006,32768};
const uint16_t gauss19[9] = {0,26164,7624,9339,3736,20255,15595,21039,32768};
const uint16_t gauss18[9] = {0,4025,13676,14964,17662,16336,16103,8503,32768};
const uint16_t gauss17[9] = {0,15004,13470,16340,12224,13959,6820,6096,32768};
const uint16_t gauss16[9] = {0,25064,14415,20612,7860,23828,9985,19495,32768};
const uint16_t gauss15[9] = {0,10471,16464,23158,11004,20674,19647,22649,32768};
const uint16_t gauss14[9] = {0,10037,16674,12813,18113,17778,20068,25539,32768};
const uint16_t gauss13[9] = {0,18548,19303,12456,17769,31230,16992,16352,32768};
const uint16_t gauss12[9] = {0,14993,16041,15208,13927,14193,13076,21015,32768};
const uint16_t gauss11[9] = {0,14135,20818,9378,18054,13493,14678,14523,32768};
const uint16_t gauss10[9] = {0,16600,18421,24556,17565,16128,17304,17672,32768};
const uint16_t gauss9[9] = {0,15601,15118,19037,15786,9460,10665,12924,32768};
const uint16_t gauss8[9] = {0,19369,18736,17385,19601,21455,14800,16035,32768};
const uint16_t gauss7[9] = {0,17539,16093,18766,14618,13106,17230,17357,32768};
const uint16_t gauss6[9] = {0,14287,13939,18432,15103,18885,16847,18033,32768};
const uint16_t gauss5[9] = {0,19586,13272,18702,16248,17154,16310,17152,32768};
const uint16_t gauss4[9] = {0,19099,16054,16615,17602,15597,14517,14848,32768};
const uint16_t gauss3[9] = {0,14859,16976,16495,16771,15640,15143,16088,32768};
const uint16_t gauss2[9] = {0,17004,15967,16692,16860,15801,14812,16711,32768};
const uint16_t gauss1[9] = {0,16572,16335,16661,16630,16928,16534,16410,32768};
const uint16_t gauss0[9] = {0,16384,16384,16384,16384,16384,16384,16384,32768};

//nonconforming

const uint16_t gauss_noconform32[9] = {26114,21653,28960,29236,31384,32768,25798,31817,21428};
const uint16_t gauss_noconform31[9] = {32768,26955,27239,23918,32768,32629,30986,18763,28836};
const uint16_t gauss_noconform30[9] = {23172,32768,26311,32675,20129,16777,32768,32768,22130};
const uint16_t gauss_noconform29[9] = {25087,28627,32768,32768,21612,18378,17547,21651,32768};
const uint16_t gauss_noconform28[9] = {32768,32768,32768,32768,28267,27097,32768,31252,31720};
const uint16_t gauss_noconform27[9] = {32699,27674,27538,31330,29848,32495,30634,22578,32768};
const uint16_t gauss_noconform26[9] = {32768,31131,32768,32558,27303,25594,32768,32768,32768};
const uint16_t gauss_noconform25[9] = {32768,32768,22224,32768,24294,23295,30225,30977,27215};
const uint16_t gauss_noconform24[9] = {32768,28816,26980,19548,32071,32768,23511,22365,32768};
const uint16_t gauss_noconform23[9] = {31683,30695,31879,29605,29981,32768,31323,26651,30241};
const uint16_t gauss_noconform22[9] = {30985,32087,19831,32768,30755,24986,24736,29348,19912};
const uint16_t gauss_noconform21[9] = {32768,26216,31185,30014,32768,32768,32391,31198,32768};
const uint16_t gauss_noconform20[9] = {32768,32768,27748,29230,22505,31250,28379,28433,31947};
const uint16_t gauss_noconform19[9] = {32768,32768,23502,24648,20905,31940,28827,32463,32591};
const uint16_t gauss_noconform18[9] = {31041,21098,27545,28405,30208,29322,29166,24089,25474};
const uint16_t gauss_noconform17[9] = {29610,28433,27407,29325,26575,27734,22965,22482,25683};
const uint16_t gauss_noconform16[9] = {29712,32768,28039,32178,23660,32768,25080,31433,25247};
const uint16_t gauss_noconform15[9] = {29423,25404,29407,32768,25760,32220,31534,32768,31340};
const uint16_t gauss_noconform14[9] = {21675,25114,29548,26968,30509,30285,31815,32768,29832};
const uint16_t gauss_noconform13[9] = {27025,30800,31304,26730,30279,32768,29760,29333,26015};
const uint16_t gauss_noconform12[9] = {28410,28425,29125,28569,27713,27890,27144,32448,30524};
const uint16_t gauss_noconform11[9] = {27757,27852,32316,24674,30470,27423,28214,28111,32750};
const uint16_t gauss_noconform10[9] = {28389,29498,30715,32768,30143,29183,29968,30214,31604};
const uint16_t gauss_noconform9[9] = {26968,28831,28508,31126,28954,24729,25534,27043,29917};
const uint16_t gauss_noconform8[9] = {26159,31348,30925,30023,31503,32742,28296,29121,31129};
const uint16_t gauss_noconform7[9] = {27545,30125,29159,30945,28174,27164,29919,30004,27974};
const uint16_t gauss_noconform6[9] = {28755,27953,27721,30722,28498,31025,29663,30456,28091};
const uint16_t gauss_noconform5[9] = {30175,31493,27275,30902,29263,29868,29304,29867,28376};
const uint16_t gauss_noconform4[9] = {29032,31168,29134,29509,30168,28828,28107,28328,29498};
const uint16_t gauss_noconform3[9] = {28789,28335,29750,29428,29613,28857,28525,29157,30679};
const uint16_t gauss_noconform2[9] = {28956,29768,29075,29560,29672,28965,28304,29572,28667};
const uint16_t gauss_noconform1[9] = {29267,29480,29321,29539,29519,29718,29454,29371,29335};
const uint16_t gauss_noconform0[9] = {29354,29354,29354,29354,29354,29354,29354,29354,29354};

//conforming, with gaussian distribution centered and reflected about 0, standard deviation progresses from 0 to 2

const uint16_t gauss_low32[9] = {0,17909,1103,469,4472,9945,8377,5469,32768};
const uint16_t gauss_low31[9] = {0,5715,5062,12699,32377,7334,3556,24557,32768};
const uint16_t gauss_low30[9] = {0,11874,7195,7441,21414,29125,8585,15036,32768};
const uint16_t gauss_low29[9] = {0,1870,32768,12838,18005,25443,27354,17914,32768};
const uint16_t gauss_low28[9] = {0,16851,12102,11214,2696,5389,15692,4168,32768};
const uint16_t gauss_low27[9] = {0,4061,4374,4347,939,7027,2747,15781,32768};
const uint16_t gauss_low26[9] = {0,3889,23853,7173,4914,8846,14507,25265,32768};
const uint16_t gauss_low25[9] = {0,28177,16595,20042,11835,14132,1806,3536,32768};
const uint16_t gauss_low24[9] = {0,1435,5657,22751,6051,9244,13635,16272,32768};
const uint16_t gauss_low23[9] = {0,2888,5611,380,1244,9942,4332,6415,32768};
const uint16_t gauss_low22[9] = {0,6090,22099,27000,3025,10243,10819,212,32768};
const uint16_t gauss_low21[9] = {0,7414,4013,1322,16920,9567,6787,4044,32768};
const uint16_t gauss_low20[9] = {0,7733,3892,483,15951,4163,2440,2314,32768};
const uint16_t gauss_low19[9] = {0,14829,13657,11022,19630,5751,1409,6955,32768};
const uint16_t gauss_low18[9] = {0,19186,4357,2379,1767,271,629,12306,32768};
const uint16_t gauss_low17[9] = {0,2317,4674,264,6589,3923,14892,16003,32768};
const uint16_t gauss_low16[9] = {0,13139,3222,6298,13293,11240,10028,4584,32768};
const uint16_t gauss_low15[9] = {0,9282,74,10211,8464,6394,4817,9430,32768};
const uint16_t gauss_low14[9] = {0,9949,248,5684,2460,1944,5464,13869,32768};
const uint16_t gauss_low13[9] = {0,3128,4288,6232,1931,22613,738,246,32768};
const uint16_t gauss_low12[9] = {0,2334,724,2003,3971,3564,5280,6918,32768};
const uint16_t gauss_low11[9] = {0,3652,6615,10961,2369,4639,2818,3056,32768};
const uint16_t gauss_low10[9] = {0,135,2932,12359,1617,591,1216,1781,32768};
const uint16_t gauss_low9[9] = {0,1401,2143,3879,1116,10836,8984,5513,32768};
const uint16_t gauss_low8[9] = {0,4389,3417,1341,4745,7595,2630,734,32768};
const uint16_t gauss_low7[9] = {0,1577,645,3463,2910,5234,1103,1297,32768};
const uint16_t gauss_low6[9] = {0,3420,3954,2949,2165,3646,515,2337,32768};
const uint16_t gauss_low5[9] = {0,4723,4979,3364,406,986,311,982,32768};
const uint16_t gauss_low4[9] = {0,3975,704,158,1675,1407,3066,2558,32768};
const uint16_t gauss_low3[9] = {0,2541,713,27,398,1340,2104,651,32768};
const uint16_t gauss_low2[9] = {0,756,838,276,534,1093,2612,305,32768};
const uint16_t gauss_low1[9] = {0,92,272,228,182,639,33,157,32768};
const uint16_t gauss_low0[9] = {0,197,197,197,197,197,197,197,32768};

//nonconforming

const uint16_t gauss_low_noconform32[9] = {8297,19449,1182,493,4878,10827,9088,5962,20011};
const uint16_t gauss_low_noconform31[9] = {24232,6195,5485,13786,32768,7989,3883,26675,1492};
const uint16_t gauss_low_noconform30[9] = {15652,12923,7804,8105,23259,31640,9349,16360,18258};
const uint16_t gauss_low_noconform29[9] = {10865,2015,32768,13971,19553,27638,29715,19454,13944};
const uint16_t gauss_low_noconform28[9] = {11879,18334,13171,12207,2914,5840,17074,4547,5717};
const uint16_t gauss_low_noconform27[9] = {8164,4397,4737,4742,1037,7655,3003,17136,14472};
const uint16_t gauss_low_noconform26[9] = {16232,4244,25944,7814,5325,9598,15786,27479,25824};
const uint16_t gauss_low_noconform25[9] = {16442,30644,18021,21802,12847,15344,1980,3861,5546};
const uint16_t gauss_low_noconform24[9] = {9035,1543,6132,24713,6594,10065,14804,17670,25211};
const uint16_t gauss_low_noconform23[9] = {5625,3156,6116,430,1369,10823,4726,6955,2021};
const uint16_t gauss_low_noconform22[9] = {3881,6636,24004,29365,3306,11117,11743,213,23802};
const uint16_t gauss_low_noconform21[9] = {11098,8042,4379,1454,18409,10416,7394,4413,10919};
const uint16_t gauss_low_noconform20[9] = {21935,8422,4213,507,17320,4542,2635,2499,6286};
const uint16_t gauss_low_noconform19[9] = {14896,16136,14827,11963,21320,6268,1515,7577,7896};
const uint16_t gauss_low_noconform18[9] = {4020,20837,4719,2568,1938,277,667,13359,9897};
const uint16_t gauss_low_noconform17[9] = {443,2501,5064,270,7145,4247,16170,17378,9375};
const uint16_t gauss_low_noconform16[9] = {699,14298,3485,6863,14432,12234,10883,4999,10464};
const uint16_t gauss_low_noconform15[9] = {26,10072,64,11116,9182,6967,5253,10267,4767};
const uint16_t gauss_low_noconform14[9] = {19394,10798,287,6161,2691,2131,5956,15092,997};
const uint16_t gauss_low_noconform13[9] = {6020,3417,4678,6757,2116,24597,819,250,8544};
const uint16_t gauss_low_noconform12[9] = {2556,2519,770,2160,4300,3857,5722,7537,2728};
const uint16_t gauss_low_noconform11[9] = {4191,3953,7208,11897,2592,5025,3046,3304,8293};
const uint16_t gauss_low_noconform10[9] = {2609,163,3204,13451,1775,625,1339,1953,5428};
const uint16_t gauss_low_noconform9[9] = {6162,1505,2312,4233,1196,11761,9748,5975,1211};
const uint16_t gauss_low_noconform8[9] = {8183,4788,3732,1475,5175,8273,2842,780,4241};
const uint16_t gauss_low_noconform7[9] = {4719,1731,684,3782,3146,5672,1217,1427,3648};
const uint16_t gauss_low_noconform6[9] = {1694,3700,4280,3223,2336,3980,577,2558,3354};
const uint16_t gauss_low_noconform5[9] = {1856,5150,5395,3674,424,1088,321,1085,2643};
const uint16_t gauss_low_noconform4[9] = {1002,4337,748,189,1837,1512,3316,2763,163};
const uint16_t gauss_low_noconform3[9] = {1609,2745,792,12,449,1439,2270,691,3114};
const uint16_t gauss_low_noconform2[9] = {1192,839,894,317,598,1170,2822,348,1914};
const uint16_t gauss_low_noconform1[9] = {415,117,279,265,214,712,53,153,246};
const uint16_t gauss_low_noconform0[9] = {197,197,197,197,197,197,197,197,197};

const uint16_t algerian_q[65] = {0,2142,2035,1961,3159,2608,2621,3746,3604,4296,6119,8789,12825,17204,20774,24266,28197,31204,32523,32768,31563,28844,25803,22397,17954,13560,10256,7348,11678,16083,19668,23236,27438,30497,30930,29418,25592,21227,17645,14080,9818,6352,5365,6506,8794,9276,8286,10313,10366,30019,27360,24118,19738,15286,11803,8570,5577,4799,6438,9335,13533,17963,21519,24950,28738};
//horizontal Algerian
const uint16_t algerian_w[65] = {0,3981,10044,15298,20526,26592,31764,31459,29045,23370,18089,13354,16470,22772,25985,20923,14621,9710,13518,18774,24969,25124,19873,13599,15753,21001,24663,20383,15163,10144,12697,18995,24106,26729,26687,23057,17910,12667,6375,2167,1604,3319,9262,14513,18313,13388,8126,3175,543,271,0,822,5787,12077,15322,10157,4085,1604,1739,5473,11723,16965,22200,28262,32768};
//horizontal Algerian
const uint16_t algerian_e[65] = {0,8179,19208,14274,15458,20508,29127,25220,28282,32768,32768,32768,32768,32768,31391,27276,22251,18860,16804,16726,15279,14207,9168,3901,2309,2320,2330,2341,2352,3219,7866,8117,4977,4132,7072,13119,15779,16240,15285,10251,5216,6504,12543,17053,17386,14686,17123,22396,20435,20203,24363,28356,28737,27364,29332,29445,25318,20464,22543,28596,30796,30392,27643,27723,32768};
//horizontal Algerian
const uint16_t algerian_r[65] = {0,913,2763,5060,8379,12305,23196,31224,29921,25983,21734,19459,20047,24806,28967,28828,27911,29721,28751,24081,19425,21275,26990,29415,25435,20673,17516,15454,14782,13934,10376,5963,4040,4040,5250,9341,14092,16916,16467,14880,10600,6021,3183,2840,2534,2227,2227,4002,7876,12646,15287,13137,8589,3961,944,3116,5774,9514,13583,17622,20068,23677,28175,31328,32768};
//horizontal Algerian
const uint16_t algerian_t[65] = {0,1029,1992,2864,3623,4186,5499,7518,9853,12207,12792,10800,8518,6496,5462,5081,6061,7045,9116,11425,13113,13193,13193,13193,13193,13193,13193,13193,13193,13193,13193,13193,12582,10747,9812,12192,14573,16953,19333,21247,20419,18987,18710,18710,18710,18710,18710,18710,18710,18710,18710,18710,18710,18710,19175,21202,23544,25744,27226,28148,29007,29843,30918,32093,32768};
//vertical Algerian
const uint16_t algerian_u[65] = {0,677,3774,7756,10742,11958,9303,8766,8766,8766,8766,8766,8803,8835,9368,11638,15368,19277,21970,23569,24338,24526,24562,24578,24594,24616,24638,23531,21331,22469,26416,30362,32768,30485,29511,29511,29511,29511,29511,29476,29233,28781,27665,24924,21300,17369,14416,11501,7897,8332,12054,14986,17955,21849,25292,27204,28080,28573,28712,28712,28712,28712,28712,28712,32768};
//vertical Algerian
const uint16_t algerian_i[65] = {0,4857,9519,14182,18844,23507,27058,24650,20855,19827,19827,19827,19827,19827,19827,19827,19827,19827,19827,19827,19827,20042,22939,26516,22994,17166,12503,7841,3178,0,3007,6592,7524,7524,7524,7524,7524,7524,7524,7524,7524,7524,7524,7524,6969,3814,346,28676,25091,24514,24514,24514,24514,24514,24514,24514,24514,24514,24514,24514,24514,25753,28851,31949,32768};
//vertical Algerian
const uint16_t algerian_o[65] = {0,484,1648,3572,6252,9517,13197,17028,20770,24108,27275,29268,30014,30214,29899,29033,27468,25196,22173,18570,17989,16666,12154,9742,8495,7927,7769,7960,8625,10184,12365,10918,9331,8712,8670,9018,9938,11926,15292,18997,25097,27836,29847,31342,32014,31953,31344,30039,28034,25349,22035,18330,14491,10768,8817,12671,16456,20277,23838,26941,29396,31156,32246,32739,32768};
//vertical Algerian
const uint16_t algerian_a[65] = {0,1518,6196,11094,14889,17058,23564,20902,16357,13399,16823,21535,25470,19444,14959,16384,21805,32768,32768,30941,25296,21802,20926,20569,17076,13188,8366,3571,1958,1958,3417,8969,13936,11499,5426,1037,662,442,10,22,1612,7144,12094,9294,10839,11156,7429,10223,7574,2844,1958,1958,4466,10056,15041,17574,20943,22854,27777,31307,26790,21814,21569,27524,32768};
//horizontal Algerian
const uint16_t algerian_s[65] = {0,1643,4008,7152,10702,14895,27708,29476,29511,27460,24094,22481,25721,28493,28981,27489,30250,26230,24646,27866,31089,31478,32185,32768,32241,30470,27588,24075,20609,17547,16018,15192,14004,11698,8308,4731,3409,3810,5401,8195,10522,6985,3293,3400,2931,2103,1646,2186,4344,7252,10742,14246,17078,19164,20359,21403,23521,26880,29759,30832,29361,26640,24943,28146,31336};
//horizontal Algerian

const uint16_t iExpo[65] = {0,3367,6388,9099,11532,13715,15674,17432,19009,20425,21695,22835,23858,24776,25599,26339,27002,27597,28131,28610,29040,29426,29773,30083,30362,30612,30837,31038,31219,31382,31527,31658,31775,31880,31975,32059,32135,32204,32265,32320,32369,32413,32453,32489,32521,32549,32575,32598,32619,32637,32654,32669,32683,32695,32705,32715,32724,32732,32739,32745,32751,32756,32760,32764,32768};
const uint16_t iQuint[65] = {0,2481,4810,6993,9038,10950,12738,14406,15961,17409,18755,20006,21165,22239,23231,24148,24992,25769,26483,27137,27735,28282,28780,29232,29643,30015,30350,30652,30923,31165,31381,31574,31744,31894,32026,32142,32243,32330,32405,32470,32525,32572,32611,32643,32670,32692,32710,32725,32736,32745,32752,32757,32760,32763,32765,32766,32767,32767,32768,32768,32768,32768,32768,32768,32768};
const uint16_t iQuart[65] = {0,2000,3908,5725,7455,9101,10665,12151,13560,14896,16160,17357,18487,19555,20561,21509,22400,23237,24023,24759,25447,26091,26690,27249,27768,28250,28695,29108,29487,29837,30158,30452,30720,30964,31186,31387,31567,31730,31875,32005,32120,32221,32310,32388,32455,32513,32563,32605,32640,32669,32693,32712,32727,32739,32748,32755,32760,32763,32765,32767,32767,32768,32768,32768,32768};
const uint16_t iCube[65] = {0,1512,2977,4395,5768,7096,8379,9619,10816,11971,13085,14158,15192,16187,17143,18062,18944,19790,20601,21377,22120,22830,23507,24153,24768,25353,25909,26436,26936,27409,27855,28276,28672,29044,29393,29719,30024,30308,30571,30815,31040,31247,31437,31610,31768,31911,32039,32154,32256,32346,32425,32493,32552,32602,32643,32677,32704,32725,32741,32752,32760,32765,32767,32768,32768};
const uint16_t iQuad[65] = {0,1016,2016,3000,3968,4920,5856,6776,7680,8568,9440,10296,11136,11960,12768,13560,14336,15096,15840,16568,17280,17976,18656,19320,19968,20600,21216,21816,22400,22968,23520,24056,24576,25080,25568,26040,26496,26936,27360,27768,28160,28536,28896,29240,29568,29880,30176,30456,30720,30968,31200,31416,31616,31800,31968,32120,32256,32376,32480,32568,32640,32696,32736,32760,32768};
const uint16_t linear[65] = {0,512,1024,1536,2048,2560,3072,3584,4096,4608,5120,5632,6144,6656,7168,7680,8192,8704,9216,9728,10240,10752,11264,11776,12288,12800,13312,13824,14336,14848,15360,15872,16384,16896,17408,17920,18432,18944,19456,19968,20480,20992,21504,22016,22528,23040,23552,24064,24576,25088,25600,26112,26624,27136,27648,28160,28672,29184,29696,30208,30720,31232,31744,32256,32768};
const uint16_t quad[65] = {0,8,32,72,128,200,288,392,512,648,800,968,1152,1352,1568,1800,2048,2312,2592,2888,3200,3528,3872,4232,4608,5000,5408,5832,6272,6728,7200,7688,8192,8712,9248,9800,10368,10952,11552,12168,12800,13448,14112,14792,15488,16200,16928,17672,18432,19208,20000,20808,21632,22472,23328,24200,25088,25992,26912,27848,28800,29768,30752,31752,32768};
const uint16_t cube[65] = {0,0,1,3,8,16,27,43,64,91,125,166,216,275,343,422,512,614,729,857,1000,1158,1331,1521,1728,1953,2197,2460,2744,3049,3375,3724,4096,4492,4913,5359,5832,6332,6859,7415,8000,8615,9261,9938,10648,11391,12167,12978,13824,14706,15625,16581,17576,18610,19683,20797,21952,23149,24389,25672,27000,28373,29791,31256,32768};
const uint16_t quart[65] = {0,0,0,0,0,1,3,5,8,13,20,29,40,56,75,99,128,163,205,255,312,380,458,547,648,763,893,1038,1200,1381,1582,1804,2048,2316,2610,2931,3280,3660,4073,4518,5000,5519,6078,6677,7320,8009,8745,9531,10368,11259,12207,13213,14280,15411,16608,17872,19208,20617,22103,23667,25312,27043,28860,30768,32768};
const uint16_t quint[65] = {0,0,0,0,0,0,0,1,1,2,3,5,8,11,16,23,32,43,58,76,98,125,157,196,243,298,363,438,525,626,742,874,1024,1194,1387,1603,1845,2116,2418,2753,3125,3536,3988,4486,5033,5631,6285,6999,7776,8620,9537,10529,11603,12762,14013,15359,16807,18362,20030,21818,23730,25775,27958,30287,32768};
const uint16_t expo[65] = {0,4,8,12,17,23,29,36,44,53,63,73,85,99,114,131,149,170,193,219,247,279,315,355,399,448,503,564,633,709,793,888,993,1110,1241,1386,1549,1730,1931,2156,2406,2685,2995,3342,3728,4158,4637,5171,5766,6429,7169,7992,8910,9933,11073,12343,13759,15336,17094,19053,21236,23669,26380,29401,32768};

const uint16_t gamma1[65] = {0,2481,4810,6993,9038,10950,12738,14406,15961,17409,18755,20006,21165,22239,23231,24148,24992,25769,26483,27137,27735,28282,28780,29232,29643,30015,30350,30652,30923,31165,31381,31574,31744,31894,32026,32142,32243,32330,32405,32470,32525,32572,32611,32643,32670,32692,32710,32725,32736,32745,32752,32757,32760,32763,32765,32766,32767,32767,32768,32768,32768,32768,32768,32768,32768};
const uint16_t gamma2[65] = {0,2000,3908,5725,7455,9101,10665,12151,13560,14896,16160,17357,18487,19555,20561,21509,22400,23237,24023,24759,25447,26091,26690,27249,27768,28250,28695,29108,29487,29837,30158,30452,30720,30964,31186,31387,31567,31730,31875,32005,32120,32221,32310,32388,32455,32513,32563,32605,32640,32669,32693,32712,32727,32739,32748,32755,32760,32763,32765,32767,32767,32768,32768,32768,32768};
const uint16_t gamma3[65] = {0,1512,2977,4395,5768,7096,8379,9619,10816,11971,13085,14158,15192,16187,17143,18062,18944,19790,20601,21377,22120,22830,23507,24153,24768,25353,25909,26436,26936,27409,27855,28276,28672,29044,29393,29719,30024,30308,30571,30815,31040,31247,31437,31610,31768,31911,32039,32154,32256,32346,32425,32493,32552,32602,32643,32677,32704,32725,32741,32752,32760,32765,32767,32768,32768};
const uint16_t gamma4[65] = {0,1016,2016,3000,3968,4920,5856,6776,7680,8568,9440,10296,11136,11960,12768,13560,14336,15096,15840,16568,17280,17976,18656,19320,19968,20600,21216,21816,22400,22968,23520,24056,24576,25080,25568,26040,26496,26936,27360,27768,28160,28536,28896,29240,29568,29880,30176,30456,30720,30968,31200,31416,31616,31800,31968,32120,32256,32376,32480,32568,32640,32696,32736,32760,32768};
// gamma5 = linear
const uint16_t gamma6[65] = {0,8,32,72,128,200,288,392,512,648,800,968,1152,1352,1568,1800,2048,2312,2592,2888,3200,3528,3872,4232,4608,5000,5408,5832,6272,6728,7200,7688,8192,8712,9248,9800,10368,10952,11552,12168,12800,13448,14112,14792,15488,16200,16928,17672,18432,19208,20000,20808,21632,22472,23328,24200,25088,25992,26912,27848,28800,29768,30752,31752,32768};
const uint16_t gamma7[65] = {0,0,1,3,8,16,27,43,64,91,125,166,216,275,343,422,512,614,729,857,1000,1158,1331,1521,1728,1953,2197,2460,2744,3049,3375,3724,4096,4492,4913,5359,5832,6332,6859,7415,8000,8615,9261,9938,10648,11391,12167,12978,13824,14706,15625,16581,17576,18610,19683,20797,21952,23149,24389,25672,27000,28373,29791,31256,32768};
const uint16_t gamma8[65] = {0,0,0,0,0,1,3,5,8,13,20,29,40,56,75,99,128,163,205,255,312,380,458,547,648,763,893,1038,1200,1381,1582,1804,2048,2316,2610,2931,3280,3660,4073,4518,5000,5519,6078,6677,7320,8009,8745,9531,10368,11259,12207,13213,14280,15411,16608,17872,19208,20617,22103,23667,25312,27043,28860,30768,32768};
const uint16_t gamma9[65] = {0,0,0,0,0,0,0,1,1,2,3,5,8,11,16,23,32,43,58,76,98,125,157,196,243,298,363,438,525,626,742,874,1024,1194,1387,1603,1845,2116,2418,2753,3125,3536,3988,4486,5033,5631,6285,6999,7776,8620,9537,10529,11603,12762,14013,15359,16807,18362,20030,21818,23730,25775,27958,30287,32768};

// a=b=1, n= {.3, .66, 1.33, 2, 5}
const uint16_t superEllipse1_1[65] = {0,0,0,0,0,0,1,1,2,3,4,6,7,10,13,16,21,26,32,39,47,56,67,79,93,109,128,149,172,198,228,262,300,342,389,442,502,568,642,725,818,922,1038,1169,1315,1480,1665,1874,2110,2378,2683,3032,3431,3893,4430,5060,5804,6696,7781,9130,10852,13143,16390,21558,32768};
const uint16_t superEllipse1_2[65] = {0,54,131,227,338,464,602,752,914,1087,1271,1465,1670,1884,2108,2342,2586,2839,3102,3374,3657,3949,4250,4561,4882,5213,5554,5905,6267,6638,7021,7415,7819,8235,8663,9103,9554,10019,10497,10988,11494,12013,12548,13099,13667,14252,14854,15477,16121,16788,17476,18191,18934,19707,20513,21357,22242,23177,24167,25224,26363,27611,29007,30638,32768};
//astroid
const uint16_t superEllipse1_3[65] = {0,1392,2543,3578,4535,5436,6292,7112,7901,8662,9400,10116,10814,11493,12157,12805,13440,14061,14669,15265,15849,16424,16987,17540,18083,18617,19142,19657,20165,20663,21153,21635,22109,22574,23032,23482,23924,24359,24786,25205,25617,26021,26417,26806,27187,27560,27926,28283,28632,28973,29305,29629,29943,30249,30544,30830,31105,31368,31619,31858,32081,32288,32476,32639,32768};
const uint16_t superEllipse1_4[65] = {0,3356,5639,7472,9037,10421,11666,12804,13853,14831,15744,16603,17414,18181,18909,19602,20262,20892,21495,22071,22623,23153,23661,24148,24616,25065,25497,25912,26310,26693,27061,27414,27753,28079,28392,28691,28978,29253,29516,29767,30007,30236,30454,30661,30858,31044,31220,31386,31542,31688,31825,31952,32070,32178,32277,32367,32447,32519,32581,32635,32679,32715,32741,32759,32768};
const uint16_t superEllipse1_5[65] = {0,8438,12860,15907,18222,20078,21614,22913,24028,24996,25845,26593,27257,27849,28376,28849,29272,29653,29996,30303,30581,30830,31054,31255,31436,31598,31743,31873,31989,32092,32183,32265,32336,32399,32455,32503,32546,32582,32614,32641,32664,32684,32700,32714,32725,32735,32743,32749,32754,32757,32760,32763,32764,32766,32767,32767,32767,32768,32768,32768,32768,32768,32768,32768,32768};

const uint16_t moogShiftedAttack1[65] = {0,135,651,1522,2715,4189,5894,7777,9782,11853,13935,15970,17910,19709,21327,22729,23890,24793,25427,25790,25892,25742,25360,24775,24014,23113,22108,21037,19940,18854,17813,16851,15998,15278,14713,14319,14100,14067,14212,14533,15019,15652,16416,17286,18240,19253,20299,21350,22383,23376,24304,25152,25902,26544,27068,27467,27745,27903,27943,27880,27719,27480,27172,26819,26432};

const uint16_t moogShiftedAttack2[65] = {0,678,2124,4205,6764,9622,12590,15481,18133,20400,22175,23387,24004,24035,23522,22545,21204,19616,17909,16206,14627,13278,12235,11559,11281,11404,11907,12747,13858,15165,16585,18033,19422,20685,21754,22589,23162,23462,23497,23293,22888,22332,21677,20985,20311,19705,19216,18877,18709,18725,18924,19291,19803,20433,21141,21890,22638,23354,23999,24554,24996,25316,25510,25588,25560};
//
const uint16_t moogShiftedAttack3[65] = {0,1406,4310,8199,12463,16502,19794,21977,22867,22486,21022,18800,16222,13702,11609,10220,9683,10023,11135,12821,14812,16830,18618,19966,20754,20946,20592,19815,18782,17688,16710,15998,15651,15707,16146,16893,17843,18867,19838,20652,21233,21542,21589,21408,21073,20668,20278,19977,19827,19855,20065,20435,20920,21471,22026,22530,22939,23233,23401,23459,23427,23344,23249,23179,23166};
//
const uint16_t moogShiftedAttack4[65] = {0,663,4827,10829,16666,20656,21893,20420,17091,13206,10056,8544,8957,10965,13801,16551,18454,19094,18499,17063,15379,14039,13447,13736,14750,16139,17483,18437,18814,18628,18059,17382,16861,16687,16914,17472,18197,18901,19424,19683,19688,19516,19298,19153,19165,19362,19709,20131,20544,20872,21078,21170,21181,21172,21198,21296,21477,21725,22010,22290,22528,22714,22845,22941,23028};
//
const uint16_t moogShiftedAttack5[65] = {0,3561,12116,19408,21177,17475,11798,8217,8699,12257,16160,17979,17071,14640,12620,12312,13688,15656,16968,17023,16135,15151,14816,15323,16290,17128,17434,17222,16831,16649,16854,17347,17868,18185,18244,18160,18121,18247,18530,18867,19141,19294,19358,19415,19536,19735,19979,20207,20385,20515,20627,20762,20933,21129,21330,21508,21666,21807,21953,22115,22293,22476,22652,22816,22974};
//
const uint16_t moogShiftedAttack6[65] = {0,12503,19735,14338,6736,7237,13216,15929,13109,10013,10802,13644,14651,13291,12130,12785,14160,14564,13980,13629,14106,14810,15021,14831,14810,15158,15559,15722,15727,15834,16102,16372,16530,16627,16783,17005,17221,17382,17525,17696,17895,18087,18255,18418,18594,18781,18963,19136,19306,19484,19667,19847,20019,20195,20372,20552,20730,20905,21080,21258,21436,21613,21791,21966,22144};
//
const uint16_t moogShiftedAttack7[65] = {0,16728,9776,3698,11772,11489,7077,10109,11583,9315,10077,11479,10655,10666,11591,11492,11396,11929,12115,12105,12417,12672,12758,12973,13221,13373,13557,13783,13965,14146,14354,14548,14732,14932,15129,15318,15513,15707,15899,16094,16288,16483,16674,16869,17063,17258,17452,17647,17839,18033,18228,18422,18614,18809,19003,19198,19390,19584,19779,19973,20165,20359,20554,20748,20940};
//
const uint16_t moogShiftedAttack8[65] = {0,16087,5289,12600,8493,11021,10128,10634,10911,10819,11338,11210,11658,11643,11975,12062,12310,12459,12666,12843,13032,13219,13403,13592,13774,13963,14148,14334,14521,14708,14892,15079,15266,15453,15639,15824,16010,16197,16384,16568,16755,16942,17129,17313,17500,17686,17873,18057,18244,18431,18618,18805,18989,19176,19362,19549,19733,19920,20107,20294,20478,20665,20852,21038,21223};
//
const uint16_t moogShiftedAttack9[65] = {0,3526,4397,3255,3860,4413,4393,4632,4956,5159,5384,5640,5875,6107,6349,6588,6824,7063,7301,7537,7776,8015,8253,8489,8728,8966,9205,9441,9680,9918,10157,10396,10632,10870,11109,11348,11583,11822,12061,12300,12535,12774,13013,13252,13487,13726,13965,14204,14443,14678,14917,15156,15394,15630,15869,16108,16346,16582,16821,17060,17298,17534,17773,18011,18250};
//
const uint16_t moogShiftedRelease1[65] = {260,919,1970,3392,5153,7212,9515,11996,14591,17220,19810,22281,24566,26600,28330,29727,30776,31491,31913,32109,32162,32167,32259,32295,32353,32427,32508,32590,32664,32725,32760,32768,32737,32661,32536,32361,32129,31839,31496,31096,30648,30157,29630,29076,28501,27920,27343,26780,26246,25752,25307,24923,24607,24368,24208,24129,24136,24223,24386,24620,24915,25256,25635,26032,26432};
//
const uint16_t moogShiftedRelease2[65] = {168,1221,3127,5805,9117,12869,16831,20751,24381,27489,29908,31552,32452,32768,32749,32686,32553,32391,32204,31991,31753,31493,31217,30927,30637,30347,30071,29816,29587,29393,29232,29112,29028,28979,28960,28958,28967,28977,28970,28939,28871,28757,28591,28369,28088,27756,27379,26968,26535,26100,25676,25284,24942,24661,24458,24334,24294,24336,24451,24622,24832,25054,25269,25445,25560};
//
const uint16_t moogShiftedRelease3[65] = {430,2788,6879,12224,18123,23748,28315,31286,32595,32768,32639,32472,32296,32125,31961,31808,31658,31515,31371,31226,31073,30911,30738,30553,30356,30153,29947,29746,29552,29369,29205,29059,28927,28810,28696,28581,28454,28310,28141,27949,27730,27494,27244,26997,26761,26548,26370,26232,26127,26056,26005,25956,25894,25799,25658,25464,25210,24909,24574,24227,23894,23603,23376,23228,23166};
//
const uint16_t moogShiftedRelease4[65] = {3547,10657,19383,27078,31584,32768,32656,32559,32394,32227,32061,31896,31731,31563,31394,31226,31056,30887,30721,30554,30391,30226,30063,29898,29730,29560,29388,29216,29047,28879,28714,28553,28393,28234,28069,27902,27727,27551,27372,27197,27030,26869,26715,26564,26413,26252,26082,25901,25711,25518,25334,25165,25011,24873,24745,24609,24458,24283,24084,23866,23646,23439,23267,23132,23028};
//
const uint16_t moogShiftedRelease5[65] = {5275,17251,28465,32757,32647,32768,32601,32437,32270,32104,31937,31773,31606,31440,31273,31109,30942,30775,30609,30442,30278,30111,29945,29778,29614,29447,29280,29114,28949,28783,28616,28449,28283,28118,27952,27785,27621,27454,27288,27121,26954,26788,26623,26459,26292,26126,25957,25790,25626,25462,25297,25131,24964,24795,24626,24460,24295,24135,23973,23807,23633,23460,23291,23129,22974};
//
const uint16_t moogShiftedRelease6[65] = {1416,19348,31916,31800,32768,32590,32413,32238,32060,31882,31705,31529,31352,31174,30996,30821,30644,30466,30288,30111,29936,29758,29580,29403,29227,29050,28872,28695,28519,28342,28164,27986,27811,27634,27456,27278,27101,26925,26748,26570,26393,26217,26040,25862,25684,25509,25332,25154,24976,24801,24623,24446,24268,24093,23915,23738,23560,23382,23207,23030,22852,22674,22499,22321,22144};
//
const uint16_t moogShiftedRelease7[65] = {3003,29035,28907,32768,32573,32382,32187,31993,31798,31604,31412,31217,31023,30828,30636,30442,30247,30053,29861,29667,29472,29278,29086,28891,28697,28502,28308,28116,27921,27727,27532,27340,27146,26951,26757,26565,26371,26176,25982,25790,25595,25401,25206,25014,24820,24625,24431,24236,24044,23850,23655,23461,23269,23075,22880,22686,22494,22299,22105,21910,21718,21524,21329,21135,20940};

const uint16_t moogShiftedRelease8[65] = {22922,22799,32768,32581,32394,32210,32023,31837,31650,31463,31279,31092,30905,30718,30534,30347,30161,29974,29790,29603,29416,29229,29045,28858,28671,28485,28300,28114,27927,27740,27553,27369,27182,26995,26809,26624,26438,26251,26064,25880,25693,25506,25319,25135,24948,24762,24575,24388,24204,24017,23830,23643,23459,23272,23085,22899,22714,22528,22341,22154,21970,21783,21596,21409,21223};
//
const uint16_t moogShiftedRelease9[65] = {5721,9042,8885,32768,32532,32294,32055,31816,31581,31342,31103,30864,30625,30390,30151,29912,29673,29438,29199,28960,28721,28486,28247,28008,27770,27534,27295,27056,26818,26579,26343,26104,25866,25627,25391,25153,24914,24675,24439,24201,23962,23723,23487,23249,23010,22771,22536,22297,22058,21819,21580,21345,21106,20867,20628,20393,20154,19915,19677,19441,19202,18963,18725,18489,18250};
//

const float t1Row1[8] = {2, 3, 4, 5, 6, 8, 10, 12};
const float t2Row1[8] = {2, 3, 4, 5, 6, 8, 10, 12};

const float grid1Row1[8] = {noteC1, noteDsharp1, noteG1, noteAsharp1, noteD2, noteGsharp2, noteAsharp2, noteC3};
const float grid1Row2[8] = {noteC1, noteDsharp1, noteD1, noteAsharp1, noteGsharp1, noteD2, noteC2, noteAsharp2};
const float grid1Row3[8] = {noteDsharp1, noteG1, noteAsharp1, noteD2, noteF2, noteGsharp2, noteG2, noteAsharp2};
const float grid1Row4[8] = {noteF1, noteG1, noteDsharp1, noteD2, noteC2, noteGsharp2, noteF2, noteC3};
const float grid1Row5[8] = {noteG1, noteF1, noteD1, noteAsharp1, noteC2, noteD2, noteF2, noteG3};
const float grid1Row6[8] = {noteD1, noteF1, noteA1, noteAsharp1, noteC2, noteAsharp2, noteF2, noteA3};
const float grid1Row7[8] = {noteA1, noteGsharp1, noteFsharp1, noteCsharp1, noteE2, noteDsharp2, noteA2, noteGsharp2};
const float grid1Row8[8] = {noteC1, noteFsharp1, noteG1, noteCsharp1, noteE2, noteGsharp2, noteD2, noteC3};

extern Family familyArray[15];
extern uint8_t familyIndicator;
extern Scale rowScaleArray[1];
extern uint8_t rowScaleIndicator;
extern Scale ratioScaleArray[1];
extern uint8_t ratioScaleIndicator;
enum scaleModes scaleMode;
enum controlModes controlMode;
enum phaseLockModes phaseLockMode;
enum sampleHoldModes sampleHoldMode;
int trig;
uint8_t phaseState = 1;
uint8_t lastAttackFlag;
uint8_t lastReleaseFlag;
uint8_t intoattackfroml;
uint8_t intoreleasefroml;
uint8_t intoattackfromr;
uint8_t intoreleasefromr;
uint8_t pintimer;
uint16_t sampleHoldTimer;
int benchmark;
int lastcount;
int out;
extern uint32_t ADCReadings1[4];
extern uint32_t ADCReadings2[2];
extern uint32_t ADCReadings3[1];

//define our wavetable family as two arrays of 9 wavetables (defined in tables.h), one for attack, one for release

/* USER CODE END PV */

void SystemClock_Config(void);
static void MX_GPIO_Init(void);
static void MX_DMA_Init(void);
static void MX_ADC1_Init(void);
static void MX_ADC2_Init(void);
static void MX_ADC3_Init(void);
static void MX_DAC_Init(void);
static void MX_TIM1_Init(void);
static void MX_TSC_Init(void);
static void MX_TIM2_Init(void);
static void MX_TIM6_Init(void);
static void MX_TIM4_Init(void);
static void MX_TIM7_Init(void);
static void MX_TIM3_Init(void);
static void MX_TIM8_Init(void);

void HAL_TIM_MspPostInit(TIM_HandleTypeDef *htim);

/* USER CODE BEGIN PFP */
/* Private function prototypes -----------------------------------------------*/
void readDetect(void);
void readRelease(uint8_t);
void handleRelease(uint8_t);
void changeMode(uint8_t);
void showMode(uint8_t);
void familyRGB(void);
void restoreDisplay(void);
void clearLEDs(void);
/* USER CODE END PFP */

int main(void)
{

  /* MCU Configuration----------------------------------------------------------*/

  /* Reset of all peripherals, Initializes the Flash interface and the Systick. */
  HAL_Init();

  /* Configure the system clock */
  SystemClock_Config();

  /* Initialize all configured peripherals */
  MX_GPIO_Init();
  MX_DMA_Init();
  MX_ADC1_Init();
  MX_ADC2_Init();
  MX_ADC3_Init();
  MX_DAC_Init();
  MX_TIM1_Init();
  MX_TSC_Init();
  MX_TIM2_Init();
  MX_TIM6_Init();
  MX_TIM4_Init();
  MX_TIM7_Init();
  MX_TIM3_Init();
  MX_TIM8_Init();

  /* USER CODE BEGIN 2 */
  //define our wavetable family as two arrays of 9 wavetables (defined in tables.h), one for attack, one for release

    const float *ratio1ScaleGrid[2] = {t1Row1, t2Row1};
    const float *row1ScaleGrid[9] = {grid1Row1, grid1Row2, grid1Row3, grid1Row4, grid1Row5, grid1Row6, grid1Row7, grid1Row8};

    const uint16_t *perlinAttackFamily[9] = {perlin6_1, perlin6_2, perlin6_3, perlin6_4, perlin6_5, perlin6_6, perlin6_7, perlin6_8, perlin6_8};
    const uint16_t *perlinReleaseFamily[9] = {perlin6_1, perlin6_2, perlin6_3, perlin6_4, perlin6_5, perlin6_6, perlin6_7, perlin6_8, perlin6_8};
    const uint16_t *sinefoldAttackFamily[9] = {sinefold_ctr_1, sinefold_ctr_2, sinefold_ctr_3, sinefold_ctr_4, sinefold_ctr_5, sinefold_ctr_6, sinefold_ctr_7, sinefold_ctr_8, sinefold_ctr_9};
    const uint16_t *sinefoldReleaseFamily[9] = {sinefold_ctr_1, sinefold_ctr_2, sinefold_ctr_3, sinefold_ctr_4, sinefold_ctr_5, sinefold_ctr_6, sinefold_ctr_7, sinefold_ctr_8, sinefold_ctr_9};
    const uint16_t *bounceAttackFamily[9] = {bounce1, bounce2, bounce3, bounce4, bounce5, bounce6, bounce7, bounce8};
    const uint16_t *bounceReleaseFamily[9] = {bounce1, bounce2, bounce3, bounce4, bounce5, bounce6, bounce7, bounce8};
    const uint16_t *trifoldAttackFamily[9] = {trifold_1, trifold_2, trifold_3, trifold_4, trifold_5, trifold_6, trifold_7, trifold_8, trifold_9};
    const uint16_t *trifoldReleaseFamily[9] = {trifold_1, trifold_2, trifold_3, trifold_4, trifold_5, trifold_6, trifold_7, trifold_8, trifold_9};
    const uint16_t *trioddAttackFamily[9] = {triodd_1, triodd_2, triodd_3, triodd_4, triodd_5, triodd_6, triodd_7, triodd_8, triodd_9};
    const uint16_t *trioddReleaseFamily[9] = {triodd_1, triodd_2, triodd_3, triodd_4, triodd_5, triodd_6, triodd_7, triodd_8, triodd_9};
    const uint16_t *trifudgeAttackFamily[9] = {trifudge_1, trifudge_2, trifudge_3, trifudge_4, trifudge_5, trifudge_6, trifudge_7, trifudge_8, trifudge_9};
    const uint16_t *trifudgeReleaseFamily[9] = {trifudge_1, trifudge_2, trifudge_3, trifudge_4, trifudge_5, trifudge_6, trifudge_7, trifudge_8, trifudge_9};
    const uint16_t *moog1AttackFamily[9] = {moog1attack, moog2attack, moog3attack, moog5attack, moog6attack, moog7attack, moog8attack, moog9attack, moog9attack};
    const uint16_t *moog1ReleaseFamily[9] = {moog1release, moog2release, moog3release, moog5release, moog6release, moog7release, moog8release, moog9release, moog9release};
    const uint16_t *moog2AttackFamily[9] = {moog1attack2, moog2attack2, moog3attack2, moog4attack2, moog5attack2, moog6attack2, moog7attack2, moog8attack2, moog9attack2};
    const uint16_t *moog2ReleaseFamily[9] = {moog1release2, moog2release2, moog3release2, moog4release2, moog5release2, moog6release2, moog7release2, moog8release2, moog9release2};
    const uint16_t *sawBendAttackFamily[5] = {fivept_sawbend_pre, fivept_sawbend_second, fivept_sawbend_third, fivept_sawbend_fourth, fivept_sawbend_fifth};
    const uint16_t *sawBendReleaseFamily[5] = {fivept_sawbend_pre, fivept_sawbend_second, fivept_sawbend_third, fivept_sawbend_fourth, fivept_sawbend_fifth};
    const uint16_t *exciteBikeAttackFamily[9] = {excitebike1, excitebike2, excitebike3, excitebike4, excitebike5, excitebike6, excitebike7, excitebike8, excitebike9};
    const uint16_t *exciteBikeReleaseFamily[9] = {excitebike1, excitebike2, excitebike3, excitebike4, excitebike5, excitebike6, excitebike7, excitebike8, excitebike9};
    const uint16_t *randAttackFamily[33] = {rand0, rand1, rand2, rand3, rand4, rand5, rand6, rand7, rand8, rand9, rand10, rand11, rand12, rand13, rand14, rand15, rand16, rand17, rand18, rand19, rand20, rand21, rand22, rand23, rand24, rand25, rand26, rand27, rand28, rand29, rand30, rand31, rand32};
    const uint16_t *randReleaseFamily[33] = {rand0, rand1, rand2, rand3, rand4, rand5, rand6, rand7, rand8, rand9, rand10, rand11, rand12, rand13, rand14, rand15, rand16, rand17, rand18, rand19, rand20, rand21, rand22, rand23, rand24, rand25, rand26, rand27, rand28, rand29, rand30, rand31, rand32};
    const uint16_t *gaussAttackFamily[33] = {gauss0, gauss1, gauss2, gauss3, gauss4, gauss5, gauss6, gauss7, gauss8, gauss9, gauss10, gauss11, gauss12, gauss13, gauss14, gauss15, gauss16, gauss17, gauss18, gauss19, gauss20, gauss21, gauss22, gauss23, gauss24, gauss25, gauss26, gauss27, gauss28, gauss29, gauss30, gauss31, gauss32};
    const uint16_t *gaussReleaseFamily[33] = {gauss0, gauss1, gauss2, gauss3, gauss4, gauss5, gauss6, gauss7, gauss8, gauss9, gauss10, gauss11, gauss12, gauss13, gauss14, gauss15, gauss16, gauss17, gauss18, gauss19, gauss20, gauss21, gauss22, gauss23, gauss24, gauss25, gauss26, gauss27, gauss28, gauss29, gauss30, gauss31, gauss32};
    const uint16_t *gauss_noconformAttackFamily[33] = {gauss_noconform0, gauss_noconform1, gauss_noconform2, gauss_noconform3, gauss_noconform4, gauss_noconform5, gauss_noconform6, gauss_noconform7, gauss_noconform8, gauss_noconform9, gauss_noconform10, gauss_noconform11, gauss_noconform12, gauss_noconform13, gauss_noconform14, gauss_noconform15, gauss_noconform16, gauss_noconform17, gauss_noconform18, gauss_noconform19, gauss_noconform20, gauss_noconform21, gauss_noconform22, gauss_noconform23, gauss_noconform24, gauss_noconform25, gauss_noconform26, gauss_noconform27, gauss_noconform28, gauss_noconform29, gauss_noconform30, gauss_noconform31, gauss_noconform32};
    const uint16_t *gauss_noconformReleaseFamily[33] = {gauss_noconform0, gauss_noconform1, gauss_noconform2, gauss_noconform3, gauss_noconform4, gauss_noconform5, gauss_noconform6, gauss_noconform7, gauss_noconform8, gauss_noconform9, gauss_noconform10, gauss_noconform11, gauss_noconform12, gauss_noconform13, gauss_noconform14, gauss_noconform15, gauss_noconform16, gauss_noconform17, gauss_noconform18, gauss_noconform19, gauss_noconform20, gauss_noconform21, gauss_noconform22, gauss_noconform23, gauss_noconform24, gauss_noconform25, gauss_noconform26, gauss_noconform27, gauss_noconform28, gauss_noconform29, gauss_noconform30, gauss_noconform31, gauss_noconform32};
    const uint16_t *gauss_lowAttackFamily[33] = {gauss_low0, gauss_low1, gauss_low2, gauss_low3, gauss_low4, gauss_low5, gauss_low6, gauss_low7, gauss_low8, gauss_low9, gauss_low10, gauss_low11, gauss_low12, gauss_low13, gauss_low14, gauss_low15, gauss_low16, gauss_low17, gauss_low18, gauss_low19, gauss_low20, gauss_low21, gauss_low22, gauss_low23, gauss_low24, gauss_low25, gauss_low26, gauss_low27, gauss_low28, gauss_low29, gauss_low30, gauss_low31, gauss_low32};
    const uint16_t *gauss_lowReleaseFamily[33] = {gauss_low0, gauss_low1, gauss_low2, gauss_low3, gauss_low4, gauss_low5, gauss_low6, gauss_low7, gauss_low8, gauss_low9, gauss_low10, gauss_low11, gauss_low12, gauss_low13, gauss_low14, gauss_low15, gauss_low16, gauss_low17, gauss_low18, gauss_low19, gauss_low20, gauss_low21, gauss_low22, gauss_low23, gauss_low24, gauss_low25, gauss_low26, gauss_low27, gauss_low28, gauss_low29, gauss_low30, gauss_low31, gauss_low32};
    const uint16_t *gauss_low_noconformAttackFamily[33] = {gauss_low_noconform0, gauss_low_noconform1, gauss_low_noconform2, gauss_low_noconform3, gauss_low_noconform4, gauss_low_noconform5, gauss_low_noconform6, gauss_low_noconform7, gauss_low_noconform8, gauss_low_noconform9, gauss_low_noconform10, gauss_low_noconform11, gauss_low_noconform12, gauss_low_noconform13, gauss_low_noconform14, gauss_low_noconform15, gauss_low_noconform16, gauss_low_noconform17, gauss_low_noconform18, gauss_low_noconform19, gauss_low_noconform20, gauss_low_noconform21, gauss_low_noconform22, gauss_low_noconform23, gauss_low_noconform24, gauss_low_noconform25, gauss_low_noconform26, gauss_low_noconform27, gauss_low_noconform28, gauss_low_noconform29, gauss_low_noconform30, gauss_low_noconform31, gauss_low_noconform32};
    const uint16_t *gauss_low_noconformReleaseFamily[33] = {gauss_low_noconform0, gauss_low_noconform1, gauss_low_noconform2, gauss_low_noconform3, gauss_low_noconform4, gauss_low_noconform5, gauss_low_noconform6, gauss_low_noconform7, gauss_low_noconform8, gauss_low_noconform9, gauss_low_noconform10, gauss_low_noconform11, gauss_low_noconform12, gauss_low_noconform13, gauss_low_noconform14, gauss_low_noconform15, gauss_low_noconform16, gauss_low_noconform17, gauss_low_noconform18, gauss_low_noconform19, gauss_low_noconform20, gauss_low_noconform21, gauss_low_noconform22, gauss_low_noconform23, gauss_low_noconform24, gauss_low_noconform25, gauss_low_noconform26, gauss_low_noconform27, gauss_low_noconform28, gauss_low_noconform29, gauss_low_noconform30, gauss_low_noconform31, gauss_low_noconform32};
    const uint16_t *algerianAttackFamily[5] = {algerian_t, algerian_r, algerian_e, algerian_q, algerian_w,};
    const uint16_t *algerianReleaseFamily[5] = {algerian_a, algerian_s, algerian_o, algerian_u, algerian_i,};

    const uint16_t *gammaSymAttackFamily[9] = {gamma1, gamma2, gamma3, gamma4, linear, gamma6, gamma7, gamma8, gamma9};
    const uint16_t *gammaSymReleaseFamily[9] = {gamma1, gamma2, gamma3, gamma4, linear, gamma6, gamma7, gamma8, gamma9};

    const uint16_t *gammaAsymAttackFamily[9] = {gamma1, gamma2, gamma3, gamma4, linear, gamma6, gamma7, gamma8, gamma9};
    const uint16_t *gammaAsymReleaseFamily[9] = {gamma9, gamma8, gamma7, gamma6, linear, gamma4, gamma3, gamma2, gamma1};

    // more dramatic transition to expo

    const uint16_t *sharpExpoSymAttackFamily[9] = {iExpo, iQuart, iCube, iQuad, linear, quad, cube, quart, expo};
    const uint16_t *sharpExpoSymReleaseFamily[9] = {iExpo, iQuart, iCube, iQuad, linear, quad, cube, quart, expo};

    const uint16_t *sharpExpoAsymAttackFamily[9] = {iExpo, iQuart, iCube, iQuad, linear, quad, cube, quart, expo};
    const uint16_t *sharpExpoAsymReleaseFamily[9] = {expo, quart, cube, quad, linear, iQuad, iCube, iQuart, iExpo};

    // more dramatic transition to linear

    const uint16_t *sharpLinSymAttackFamily[9] = {iExpo, iQuint, iQuart, iCube, linear, cube, quart, quint, expo};
    const uint16_t *sharpLinSymReleaseFamily[9] = {iExpo, iQuint, iQuart, iCube, linear, cube, quart, quint, expo};

    const uint16_t *sharpLinAsymAttackFamily[9] = {iExpo, iQuint, iQuart, iCube, linear, cube, quart, quint, expo};
    const uint16_t *sharpLinAsymReleaseFamily[9] = {expo, quint, quart, cube, linear, iCube, iQuart, iQuint, iExpo};

    // limit to quartic

    const uint16_t *quartSymAttackFamily[9] = {iQuint, iQuart, iCube, iQuad, linear, cube, quart, quint, expo};
    const uint16_t *quartSymReleaseFamily[9] = {iQuint, iQuart, iCube, iQuad, linear, cube, quart, quint, expo};

    const uint16_t *quartAsymAttackFamily[9] = {iQuint, iQuart, iCube, iQuad, linear, cube, quart, quint, expo};
    const uint16_t *quartAsymReleaseFamily[9] = {quint, quart, cube, quad, linear, iQuad, iCube, iQuart, iQuint};

    const uint16_t *superEllipse1SymAttackFamily[5] = {superEllipse1_1, superEllipse1_2, superEllipse1_3, superEllipse1_4, superEllipse1_5};
    const uint16_t *superEllipse1SymReleaseFamily[5] = {superEllipse1_1, superEllipse1_2, superEllipse1_3, superEllipse1_4, superEllipse1_5};

    const uint16_t *superEllipse1AsymAttackFamily[5] = {superEllipse1_1, superEllipse1_2, superEllipse1_3, superEllipse1_4, superEllipse1_5};
    const uint16_t *superEllipse1AsymReleaseFamily[5] = {superEllipse1_5, superEllipse1_4, superEllipse1_3, superEllipse1_2, superEllipse1_1};

    const uint16_t *moogShiftedAttackFamily[9] = {moogShiftedAttack1, moogShiftedAttack2, moogShiftedAttack3, moogShiftedAttack4, moogShiftedAttack5, moogShiftedAttack6, moogShiftedAttack7, moogShiftedAttack8, moogShiftedAttack9};
    const uint16_t *moogShiftedReleaseFamily[9] = {moogShiftedRelease1, moogShiftedRelease2, moogShiftedRelease3, moogShiftedRelease4, moogShiftedRelease5, moogShiftedRelease6, moogShiftedRelease7, moogShiftedRelease8, moogShiftedRelease9};

    moogShifted.attackFamily = moogShiftedAttackFamily;
    moogShifted.releaseFamily = moogShiftedReleaseFamily;
    moogShifted.tableLength = 64;
    moogShifted.familySize = 9;
    familyArray[3] = moogShifted;

    perlin.attackFamily = perlinAttackFamily;
    perlin.releaseFamily = perlinReleaseFamily;
    perlin.tableLength = 64;
    perlin.familySize = 9;
    familyArray[0] = perlin;

    sineFold.attackFamily = sinefoldAttackFamily;
    sineFold.releaseFamily= sinefoldReleaseFamily;
    sineFold.tableLength = 64;
    sineFold.familySize = 9;
    familyArray[1] = sineFold;

    bounce.attackFamily= bounceAttackFamily;
    bounce.releaseFamily = bounceReleaseFamily;
    bounce.tableLength = 64;
    bounce.familySize = 9;
    familyArray[2] = bounce;

    triFold.attackFamily = trifoldAttackFamily;
    triFold.releaseFamily = trifoldReleaseFamily;
    triFold.tableLength = 64;
    triFold.familySize = 9;
    //familyArray[0] = triFold;

    triOdd.attackFamily = trioddAttackFamily;
    triOdd.releaseFamily = trioddReleaseFamily;
    triOdd.tableLength = 64;
    triOdd.familySize = 9;
    familyArray[4] = triOdd;

    triFudge.attackFamily = trifudgeAttackFamily;
    triFudge.releaseFamily = trifudgeReleaseFamily;
    triFudge.tableLength = 64;
    triFudge.familySize = 9;
    //familyArray[5] = triFudge;

    moog1.attackFamily = moog1AttackFamily;
    moog1.releaseFamily = moog1ReleaseFamily;
    moog1.tableLength = 64;
    moog1.familySize = 9;
    //familyArray[6] = moog1;

    moog2.attackFamily = moog2AttackFamily;
    moog2.releaseFamily = moog2ReleaseFamily;
    moog2.tableLength = 64;
    moog2.familySize = 9;
    //familyArray[7] = moog2;

    sawBend.attackFamily = sawBendAttackFamily;
    sawBend.releaseFamily = sawBendReleaseFamily;
    sawBend.tableLength = 4;
    sawBend.familySize = 5;
    //familyArray[8] = sawBend;

    exciteBike.attackFamily = exciteBikeAttackFamily;
    exciteBike.releaseFamily = exciteBikeReleaseFamily;
    exciteBike.tableLength = 8;
    exciteBike.familySize = 9;
    //familyArray[9] = exciteBike;

    rand.attackFamily = randAttackFamily;
    rand.releaseFamily = randReleaseFamily;
    rand.tableLength = 8;
    rand.familySize = 33;
    //familyArray[10] = rand;

    gauss.attackFamily = gaussAttackFamily;
    gauss.releaseFamily = gaussReleaseFamily;
    gauss.tableLength = 8;
    gauss.familySize = 33;
    //familyArray[11] = gauss;

    gauss_noconform.attackFamily = gauss_noconformAttackFamily;
    gauss_noconform.releaseFamily = gauss_noconformReleaseFamily;
    gauss_noconform.tableLength = 8;
    gauss_noconform.familySize = 33;
    //familyArray[12] = gauss_noconform;

    gauss_low.attackFamily = gauss_lowAttackFamily;
    gauss_low.releaseFamily = gauss_lowReleaseFamily;
    gauss_low.tableLength = 8;
    gauss_low.familySize = 33;
    //familyArray[13] = gauss_low;

    gauss_low_noconform.attackFamily = gauss_low_noconformAttackFamily;
    gauss_low_noconform.releaseFamily = gauss_low_noconformReleaseFamily;
    gauss_low_noconform.tableLength = 8;
    gauss_low_noconform.familySize = 33;
    //familyArray[14] = gauss_low_noconform;

    algerian.attackFamily = algerianAttackFamily;
    algerian.releaseFamily = algerianReleaseFamily;
    algerian.tableLength = 64;
    algerian.familySize = 5;
    familyArray[14] = algerian;

    quartSym.attackFamily = quartSymAttackFamily;
    quartSym.releaseFamily = quartSymReleaseFamily;
    quartSym.tableLength = 64;
    quartSym.familySize = 9;
    familyArray[5] = quartSym;

    quartAsym.attackFamily = quartAsymAttackFamily;
    quartAsym.releaseFamily = quartAsymReleaseFamily;
    quartAsym.tableLength = 64;
    quartAsym.familySize = 9;
    familyArray[9] = quartAsym;

    superEllipse1Sym.attackFamily = superEllipse1SymAttackFamily;
    superEllipse1Sym.releaseFamily = superEllipse1SymReleaseFamily;
    superEllipse1Sym.tableLength = 64;
    superEllipse1Sym.familySize = 5;
    familyArray[6] = superEllipse1Sym;

    superEllipse1Asym.attackFamily = superEllipse1AsymAttackFamily;
    superEllipse1Asym.releaseFamily = superEllipse1AsymReleaseFamily;
    superEllipse1Asym.tableLength = 64;
    superEllipse1Asym.familySize = 5;
    familyArray[10] = superEllipse1Asym;

    gammaSym.attackFamily = gammaSymAttackFamily;
    gammaSym.releaseFamily = gammaSymReleaseFamily;
    gammaSym.tableLength = 64;
    gammaSym.familySize = 9;
    familyArray[7] = gammaSym;

    gammaAsym.attackFamily = gammaAsymAttackFamily;
    gammaAsym.releaseFamily = gammaAsymReleaseFamily;
    gammaAsym.tableLength = 64;
    gammaAsym.familySize = 9;
    familyArray[11] = gammaAsym;

    sharpExpoSym.attackFamily = sharpExpoSymAttackFamily;
    sharpExpoSym.releaseFamily = sharpExpoSymReleaseFamily;
    sharpExpoSym.tableLength = 64;
    sharpExpoSym.familySize = 9;
    familyArray[8] = sharpExpoSym;

    sharpExpoAsym.attackFamily = sharpExpoAsymAttackFamily;
    sharpExpoAsym.releaseFamily = sharpExpoAsymReleaseFamily;
    sharpExpoAsym.tableLength = 64;
    sharpExpoAsym.familySize = 9;
    familyArray[12] = sharpExpoAsym;

    sharpLinSym.attackFamily = sharpLinSymAttackFamily;
    sharpLinSym.releaseFamily = sharpLinSymReleaseFamily;
    sharpLinSym.tableLength = 64;
    sharpLinSym.familySize = 9;
    familyArray[9] = sharpLinSym;

    sharpLinAsym.attackFamily = sharpLinAsymAttackFamily;
    sharpLinAsym.releaseFamily = sharpLinAsymReleaseFamily;
    sharpLinAsym.tableLength = 64;
    sharpLinAsym.familySize = 9;
    familyArray[13] = sharpLinAsym;

    ratio1.scaleGrid = ratio1ScaleGrid;
    ratio1.numRows = 2;
    ratio1.pitchesPerRow = 8;
    ratioScaleArray[0] = ratio1;

    row1.scaleGrid = row1ScaleGrid;
    row1.numRows = 8;
    row1.pitchesPerRow = 8;
    rowScaleArray[0] = row1;

	span = familyArray[0].tableLength << 16;
	spanx2 = familyArray[0].tableLength << 17;
	morphBitShiftRight = 9;
	morphBitShiftLeft = 7;
	rowIndexBitShift = 9;
	rowSelectBitShift = 9;
	rowScaleIndicator = 0;
	ratioScaleIndicator = 0;

	HAL_NVIC_SetPriority(TIM6_DAC_IRQn, 0, 0);
	HAL_NVIC_SetPriority(TIM2_IRQn, 1, 0);

      HAL_ADC_Start_DMA(&hadc1, ADCReadings1, 4);
      HAL_ADC_Start_DMA(&hadc2, ADCReadings2, 2);
      HAL_ADC_Start_DMA(&hadc3, ADCReadings3, 1);
      HAL_TIM_Base_Start(&htim1);
      HAL_TIM_PWM_Start(&htim1, TIM_CHANNEL_1);
      HAL_TIM_PWM_Start(&htim1, TIM_CHANNEL_2);
      HAL_TIM_PWM_Start(&htim1, TIM_CHANNEL_3);
      HAL_TIM_Base_Start(&htim4);
      HAL_DAC_Start(&hdac, DAC_CHANNEL_1);
      HAL_DAC_Start(&hdac, DAC_CHANNEL_2);
      //HAL_DAC_Start_DMA(&hdac, DAC_CHANNEL_1, (uint32_t*)dacbuffer1, 1, DAC_ALIGN_12B_R);
      //HAL_DAC_Start_DMA(&hdac, DAC_CHANNEL_2, (uint32_t*)dacbuffer2, 1, DAC_ALIGN_12B_R);

      tsl_user_Init();
      HAL_TIM_Base_Start_IT(&htim6);
      //__HAL_TIM_ENABLE_IT(&htim8, TIM_IT_UPDATE);
      //__HAL_TIM_ENABLE_IT(&htim7, TIM_IT_UPDATE);
      //__HAL_TIM_ENABLE(&htim8);
      //HAL_TIM_Base_Start_IT(&htim2);
      HAL_TIM_IC_Start_IT(&htim2, TIM_CHANNEL_1);

  /* USER CODE END 2 */

  /* Infinite loop */
  /* USER CODE BEGIN WHILE */
  while (1)
  {
		tsl_status = tsl_user_Exec();

	  	if (tsl_status != TSL_USER_STATUS_BUSY) {

	  		if (detectOn == 0) {readDetect();}
	  		else {readRelease(modeflag);}

	  	}

	  	if (displayNewMode == 1) {
	  		restoreDisplay();
	  	}

  /* USER CODE END WHILE */

  }

}

/** System Clock Configuration
*/
void SystemClock_Config(void)
{

  RCC_OscInitTypeDef RCC_OscInitStruct;
  RCC_ClkInitTypeDef RCC_ClkInitStruct;
  RCC_PeriphCLKInitTypeDef PeriphClkInit;

    /**Initializes the CPU, AHB and APB busses clocks
    */
  RCC_OscInitStruct.OscillatorType = RCC_OSCILLATORTYPE_HSI;
  RCC_OscInitStruct.HSIState = RCC_HSI_ON;
  RCC_OscInitStruct.HSICalibrationValue = 16;
  RCC_OscInitStruct.PLL.PLLState = RCC_PLL_ON;
  RCC_OscInitStruct.PLL.PLLSource = RCC_PLLSOURCE_HSI;
  RCC_OscInitStruct.PLL.PLLMUL = RCC_PLL_MUL16;
  if (HAL_RCC_OscConfig(&RCC_OscInitStruct) != HAL_OK)
  {
    _Error_Handler(__FILE__, __LINE__);
  }

    /**Initializes the CPU, AHB and APB busses clocks
    */
  RCC_ClkInitStruct.ClockType = RCC_CLOCKTYPE_HCLK|RCC_CLOCKTYPE_SYSCLK
                              |RCC_CLOCKTYPE_PCLK1|RCC_CLOCKTYPE_PCLK2;
  RCC_ClkInitStruct.SYSCLKSource = RCC_SYSCLKSOURCE_PLLCLK;
  RCC_ClkInitStruct.AHBCLKDivider = RCC_SYSCLK_DIV1;
  RCC_ClkInitStruct.APB1CLKDivider = RCC_HCLK_DIV2;
  RCC_ClkInitStruct.APB2CLKDivider = RCC_HCLK_DIV1;

  if (HAL_RCC_ClockConfig(&RCC_ClkInitStruct, FLASH_LATENCY_2) != HAL_OK)
  {
    _Error_Handler(__FILE__, __LINE__);
  }

  PeriphClkInit.PeriphClockSelection = RCC_PERIPHCLK_TIM1|RCC_PERIPHCLK_TIM8
                              |RCC_PERIPHCLK_ADC12|RCC_PERIPHCLK_ADC34;
  PeriphClkInit.Adc12ClockSelection = RCC_ADC12PLLCLK_DIV16;
  PeriphClkInit.Adc34ClockSelection = RCC_ADC34PLLCLK_DIV16;
  PeriphClkInit.Tim1ClockSelection = RCC_TIM1CLK_HCLK;
  PeriphClkInit.Tim8ClockSelection = RCC_TIM8CLK_HCLK;
  if (HAL_RCCEx_PeriphCLKConfig(&PeriphClkInit) != HAL_OK)
  {
    _Error_Handler(__FILE__, __LINE__);
  }

    /**Configure the Systick interrupt time
    */
  HAL_SYSTICK_Config(HAL_RCC_GetHCLKFreq()/1000);

    /**Configure the Systick
    */
  HAL_SYSTICK_CLKSourceConfig(SYSTICK_CLKSOURCE_HCLK);

  /* SysTick_IRQn interrupt configuration */
  HAL_NVIC_SetPriority(SysTick_IRQn, 0, 0);
}

/* ADC1 init function */
static void MX_ADC1_Init(void)
{

  ADC_MultiModeTypeDef multimode;
  ADC_ChannelConfTypeDef sConfig;

    /**Common config
    */
  hadc1.Instance = ADC1;
  hadc1.Init.ClockPrescaler = ADC_CLOCK_ASYNC_DIV1;
  hadc1.Init.Resolution = ADC_RESOLUTION_12B;
  hadc1.Init.ScanConvMode = ADC_SCAN_ENABLE;
  hadc1.Init.ContinuousConvMode = ENABLE;
  hadc1.Init.DiscontinuousConvMode = DISABLE;
  hadc1.Init.ExternalTrigConvEdge = ADC_EXTERNALTRIGCONVEDGE_NONE;
  hadc1.Init.ExternalTrigConv = ADC_SOFTWARE_START;
  hadc1.Init.DataAlign = ADC_DATAALIGN_RIGHT;
  hadc1.Init.NbrOfConversion = 4;
  hadc1.Init.DMAContinuousRequests = ENABLE;
  hadc1.Init.EOCSelection = ADC_EOC_SEQ_CONV;
  hadc1.Init.LowPowerAutoWait = DISABLE;
  hadc1.Init.Overrun = ADC_OVR_DATA_OVERWRITTEN;
  if (HAL_ADC_Init(&hadc1) != HAL_OK)
  {
    _Error_Handler(__FILE__, __LINE__);
  }

    /**Configure the ADC multi-mode
    */
  multimode.Mode = ADC_MODE_INDEPENDENT;
  if (HAL_ADCEx_MultiModeConfigChannel(&hadc1, &multimode) != HAL_OK)
  {
    _Error_Handler(__FILE__, __LINE__);
  }

    /**Configure Regular Channel
    */
  sConfig.Channel = ADC_CHANNEL_1;
  sConfig.Rank = 1;
  sConfig.SingleDiff = ADC_SINGLE_ENDED;
  sConfig.SamplingTime = ADC_SAMPLETIME_181CYCLES_5;
  sConfig.OffsetNumber = ADC_OFFSET_NONE;
  sConfig.Offset = 0;
  if (HAL_ADC_ConfigChannel(&hadc1, &sConfig) != HAL_OK)
  {
    _Error_Handler(__FILE__, __LINE__);
  }

    /**Configure Regular Channel
    */
  sConfig.Channel = ADC_CHANNEL_2;
  sConfig.Rank = 2;
  if (HAL_ADC_ConfigChannel(&hadc1, &sConfig) != HAL_OK)
  {
    _Error_Handler(__FILE__, __LINE__);
  }

    /**Configure Regular Channel
    */
  sConfig.Channel = ADC_CHANNEL_3;
  sConfig.Rank = 3;
  if (HAL_ADC_ConfigChannel(&hadc1, &sConfig) != HAL_OK)
  {
    _Error_Handler(__FILE__, __LINE__);
  }

    /**Configure Regular Channel
    */
  sConfig.Channel = ADC_CHANNEL_4;
  sConfig.Rank = 4;
  if (HAL_ADC_ConfigChannel(&hadc1, &sConfig) != HAL_OK)
  {
    _Error_Handler(__FILE__, __LINE__);
  }

}

/* ADC2 init function */
static void MX_ADC2_Init(void)
{

  ADC_ChannelConfTypeDef sConfig;

    /**Common config
    */
  hadc2.Instance = ADC2;
  hadc2.Init.ClockPrescaler = ADC_CLOCK_ASYNC_DIV1;
  hadc2.Init.Resolution = ADC_RESOLUTION_12B;
  hadc2.Init.ScanConvMode = ADC_SCAN_ENABLE;
  hadc2.Init.ContinuousConvMode = ENABLE;
  hadc2.Init.DiscontinuousConvMode = DISABLE;
  hadc2.Init.ExternalTrigConvEdge = ADC_EXTERNALTRIGCONVEDGE_NONE;
  hadc2.Init.ExternalTrigConv = ADC_SOFTWARE_START;
  hadc2.Init.DataAlign = ADC_DATAALIGN_RIGHT;
  hadc2.Init.NbrOfConversion = 2;
  hadc2.Init.DMAContinuousRequests = ENABLE;
  hadc2.Init.EOCSelection = ADC_EOC_SEQ_CONV;
  hadc2.Init.LowPowerAutoWait = DISABLE;
  hadc2.Init.Overrun = ADC_OVR_DATA_OVERWRITTEN;
  if (HAL_ADC_Init(&hadc2) != HAL_OK)
  {
    _Error_Handler(__FILE__, __LINE__);
  }

    /**Configure Regular Channel
    */
  sConfig.Channel = ADC_CHANNEL_3;
  sConfig.Rank = 1;
  sConfig.SingleDiff = ADC_SINGLE_ENDED;
  sConfig.SamplingTime = ADC_SAMPLETIME_61CYCLES_5;
  sConfig.OffsetNumber = ADC_OFFSET_NONE;
  sConfig.Offset = 0;
  if (HAL_ADC_ConfigChannel(&hadc2, &sConfig) != HAL_OK)
  {
    _Error_Handler(__FILE__, __LINE__);
  }

    /**Configure Regular Channel
    */
  sConfig.Channel = ADC_CHANNEL_4;
  sConfig.Rank = 2;
  sConfig.OffsetNumber = ADC_OFFSET_1;
  if (HAL_ADC_ConfigChannel(&hadc2, &sConfig) != HAL_OK)
  {
    _Error_Handler(__FILE__, __LINE__);
  }

}

/* ADC3 init function */
static void MX_ADC3_Init(void)
{

  ADC_MultiModeTypeDef multimode;
  ADC_ChannelConfTypeDef sConfig;

    /**Common config
    */
  hadc3.Instance = ADC3;
  hadc3.Init.ClockPrescaler = ADC_CLOCK_ASYNC_DIV1;
  hadc3.Init.Resolution = ADC_RESOLUTION_12B;
  hadc3.Init.ScanConvMode = ADC_SCAN_DISABLE;
  hadc3.Init.ContinuousConvMode = ENABLE;
  hadc3.Init.DiscontinuousConvMode = DISABLE;
  hadc3.Init.ExternalTrigConvEdge = ADC_EXTERNALTRIGCONVEDGE_NONE;
  hadc3.Init.ExternalTrigConv = ADC_SOFTWARE_START;
  hadc3.Init.DataAlign = ADC_DATAALIGN_RIGHT;
  hadc3.Init.NbrOfConversion = 1;
  hadc3.Init.DMAContinuousRequests = ENABLE;
  hadc3.Init.EOCSelection = ADC_EOC_SINGLE_CONV;
  hadc3.Init.LowPowerAutoWait = DISABLE;
  hadc3.Init.Overrun = ADC_OVR_DATA_OVERWRITTEN;
  if (HAL_ADC_Init(&hadc3) != HAL_OK)
  {
    _Error_Handler(__FILE__, __LINE__);
  }

    /**Configure the ADC multi-mode
    */
  multimode.Mode = ADC_MODE_INDEPENDENT;
  if (HAL_ADCEx_MultiModeConfigChannel(&hadc3, &multimode) != HAL_OK)
  {
    _Error_Handler(__FILE__, __LINE__);
  }

    /**Configure Regular Channel
    */
  sConfig.Channel = ADC_CHANNEL_12;
  sConfig.Rank = 1;
  sConfig.SingleDiff = ADC_SINGLE_ENDED;
  sConfig.SamplingTime = ADC_SAMPLETIME_61CYCLES_5;
  sConfig.OffsetNumber = ADC_OFFSET_NONE;
  sConfig.Offset = 0;
  if (HAL_ADC_ConfigChannel(&hadc3, &sConfig) != HAL_OK)
  {
    _Error_Handler(__FILE__, __LINE__);
  }

}

/* DAC init function */
static void MX_DAC_Init(void)
{

  DAC_ChannelConfTypeDef sConfig;

    /**DAC Initialization
    */
  hdac.Instance = DAC;
  if (HAL_DAC_Init(&hdac) != HAL_OK)
  {
    _Error_Handler(__FILE__, __LINE__);
  }

    /**DAC channel OUT1 config
    */
  sConfig.DAC_Trigger = DAC_TRIGGER_T6_TRGO;
  sConfig.DAC_OutputBuffer = DAC_OUTPUTBUFFER_DISABLE;
  if (HAL_DAC_ConfigChannel(&hdac, &sConfig, DAC_CHANNEL_1) != HAL_OK)
  {
    _Error_Handler(__FILE__, __LINE__);
  }

    /**DAC channel OUT2 config
    */
  if (HAL_DAC_ConfigChannel(&hdac, &sConfig, DAC_CHANNEL_2) != HAL_OK)
  {
    _Error_Handler(__FILE__, __LINE__);
  }

}

/* TIM1 init function */
static void MX_TIM1_Init(void)
{

  TIM_MasterConfigTypeDef sMasterConfig;
  TIM_OC_InitTypeDef sConfigOC;
  TIM_BreakDeadTimeConfigTypeDef sBreakDeadTimeConfig;

  htim1.Instance = TIM1;
  htim1.Init.Prescaler = 1
		  -1;
  htim1.Init.CounterMode = TIM_COUNTERMODE_UP;
  htim1.Init.Period = 4095;
  htim1.Init.ClockDivision = TIM_CLOCKDIVISION_DIV1;
  htim1.Init.RepetitionCounter = 0;
  htim1.Init.AutoReloadPreload = TIM_AUTORELOAD_PRELOAD_DISABLE;
  if (HAL_TIM_PWM_Init(&htim1) != HAL_OK)
  {
    _Error_Handler(__FILE__, __LINE__);
  }

  sMasterConfig.MasterOutputTrigger = TIM_TRGO_RESET;
  sMasterConfig.MasterOutputTrigger2 = TIM_TRGO2_RESET;
  sMasterConfig.MasterSlaveMode = TIM_MASTERSLAVEMODE_DISABLE;
  if (HAL_TIMEx_MasterConfigSynchronization(&htim1, &sMasterConfig) != HAL_OK)
  {
    _Error_Handler(__FILE__, __LINE__);
  }

  sConfigOC.OCMode = TIM_OCMODE_PWM1;
  sConfigOC.Pulse = 0;
  sConfigOC.OCPolarity = TIM_OCPOLARITY_HIGH;
  sConfigOC.OCNPolarity = TIM_OCNPOLARITY_HIGH;
  sConfigOC.OCFastMode = TIM_OCFAST_DISABLE;
  sConfigOC.OCIdleState = TIM_OCIDLESTATE_RESET;
  sConfigOC.OCNIdleState = TIM_OCNIDLESTATE_RESET;
  if (HAL_TIM_PWM_ConfigChannel(&htim1, &sConfigOC, TIM_CHANNEL_1) != HAL_OK)
  {
    _Error_Handler(__FILE__, __LINE__);
  }

  if (HAL_TIM_PWM_ConfigChannel(&htim1, &sConfigOC, TIM_CHANNEL_2) != HAL_OK)
  {
    _Error_Handler(__FILE__, __LINE__);
  }

  if (HAL_TIM_PWM_ConfigChannel(&htim1, &sConfigOC, TIM_CHANNEL_3) != HAL_OK)
  {
    _Error_Handler(__FILE__, __LINE__);
  }

  sBreakDeadTimeConfig.OffStateRunMode = TIM_OSSR_DISABLE;
  sBreakDeadTimeConfig.OffStateIDLEMode = TIM_OSSI_DISABLE;
  sBreakDeadTimeConfig.LockLevel = TIM_LOCKLEVEL_OFF;
  sBreakDeadTimeConfig.DeadTime = 0;
  sBreakDeadTimeConfig.BreakState = TIM_BREAK_DISABLE;
  sBreakDeadTimeConfig.BreakPolarity = TIM_BREAKPOLARITY_HIGH;
  sBreakDeadTimeConfig.BreakFilter = 0;
  sBreakDeadTimeConfig.Break2State = TIM_BREAK2_DISABLE;
  sBreakDeadTimeConfig.Break2Polarity = TIM_BREAK2POLARITY_HIGH;
  sBreakDeadTimeConfig.Break2Filter = 0;
  sBreakDeadTimeConfig.AutomaticOutput = TIM_AUTOMATICOUTPUT_DISABLE;
  if (HAL_TIMEx_ConfigBreakDeadTime(&htim1, &sBreakDeadTimeConfig) != HAL_OK)
  {
    _Error_Handler(__FILE__, __LINE__);
  }

  HAL_TIM_MspPostInit(&htim1);

}

/* TIM2 init function */
static void MX_TIM2_Init(void)
{

  TIM_MasterConfigTypeDef sMasterConfig;
  TIM_IC_InitTypeDef sConfigIC;

  htim2.Instance = TIM2;
  htim2.Init.Prescaler = 1;
  htim2.Init.CounterMode = TIM_COUNTERMODE_UP;
  htim2.Init.Period = 4294967295;
  htim2.Init.ClockDivision = TIM_CLOCKDIVISION_DIV1;
  htim2.Init.AutoReloadPreload = TIM_AUTORELOAD_PRELOAD_DISABLE;
  if (HAL_TIM_IC_Init(&htim2) != HAL_OK)
  {
    _Error_Handler(__FILE__, __LINE__);
  }

  sMasterConfig.MasterOutputTrigger = TIM_TRGO_RESET;
  sMasterConfig.MasterSlaveMode = TIM_MASTERSLAVEMODE_DISABLE;
  if (HAL_TIMEx_MasterConfigSynchronization(&htim2, &sMasterConfig) != HAL_OK)
  {
    _Error_Handler(__FILE__, __LINE__);
  }

  sConfigIC.ICPolarity = TIM_INPUTCHANNELPOLARITY_BOTHEDGE;
  sConfigIC.ICSelection = TIM_ICSELECTION_DIRECTTI;
  sConfigIC.ICPrescaler = TIM_ICPSC_DIV1;
  sConfigIC.ICFilter = 0;
  if (HAL_TIM_IC_ConfigChannel(&htim2, &sConfigIC, TIM_CHANNEL_1) != HAL_OK)
  {
    _Error_Handler(__FILE__, __LINE__);
  }

}

/* TIM3 init function */
static void MX_TIM3_Init(void)
{

  TIM_ClockConfigTypeDef sClockSourceConfig;
  TIM_MasterConfigTypeDef sMasterConfig;

  htim3.Instance = TIM3;
  htim3.Init.Prescaler = 0;
  htim3.Init.CounterMode = TIM_COUNTERMODE_UP;
  htim3.Init.Period = 0;
  htim3.Init.ClockDivision = TIM_CLOCKDIVISION_DIV1;
  htim3.Init.AutoReloadPreload = TIM_AUTORELOAD_PRELOAD_DISABLE;
  if (HAL_TIM_Base_Init(&htim3) != HAL_OK)
  {
    _Error_Handler(__FILE__, __LINE__);
  }

  sClockSourceConfig.ClockSource = TIM_CLOCKSOURCE_INTERNAL;
  if (HAL_TIM_ConfigClockSource(&htim3, &sClockSourceConfig) != HAL_OK)
  {
    _Error_Handler(__FILE__, __LINE__);
  }

  sMasterConfig.MasterOutputTrigger = TIM_TRGO_RESET;
  sMasterConfig.MasterSlaveMode = TIM_MASTERSLAVEMODE_DISABLE;
  if (HAL_TIMEx_MasterConfigSynchronization(&htim3, &sMasterConfig) != HAL_OK)
  {
    _Error_Handler(__FILE__, __LINE__);
  }

}

/* TIM4 init function */
static void MX_TIM4_Init(void)
{

  TIM_ClockConfigTypeDef sClockSourceConfig;
  TIM_MasterConfigTypeDef sMasterConfig;

  htim4.Instance = TIM4;
  htim4.Init.Prescaler = 10000;
  htim4.Init.CounterMode = TIM_COUNTERMODE_UP;
  htim4.Init.Period = 60000;
  htim4.Init.ClockDivision = TIM_CLOCKDIVISION_DIV1;
  htim4.Init.AutoReloadPreload = TIM_AUTORELOAD_PRELOAD_DISABLE;
  if (HAL_TIM_Base_Init(&htim4) != HAL_OK)
  {
    _Error_Handler(__FILE__, __LINE__);
  }

  sClockSourceConfig.ClockSource = TIM_CLOCKSOURCE_INTERNAL;
  if (HAL_TIM_ConfigClockSource(&htim4, &sClockSourceConfig) != HAL_OK)
  {
    _Error_Handler(__FILE__, __LINE__);
  }

  sMasterConfig.MasterOutputTrigger = TIM_TRGO_RESET;
  sMasterConfig.MasterSlaveMode = TIM_MASTERSLAVEMODE_DISABLE;
  if (HAL_TIMEx_MasterConfigSynchronization(&htim4, &sMasterConfig) != HAL_OK)
  {
    _Error_Handler(__FILE__, __LINE__);
  }

}

/* TIM6 init function */
static void MX_TIM6_Init(void)
{

  TIM_MasterConfigTypeDef sMasterConfig;

  htim6.Instance = TIM6;
  htim6.Init.Prescaler = 1-1;
  htim6.Init.CounterMode = TIM_COUNTERMODE_UP;
  htim6.Init.Period = 1024;
  htim6.Init.AutoReloadPreload = TIM_AUTORELOAD_PRELOAD_DISABLE;
  if (HAL_TIM_Base_Init(&htim6) != HAL_OK)
  {
    _Error_Handler(__FILE__, __LINE__);
  }

  sMasterConfig.MasterOutputTrigger = TIM_TRGO_UPDATE;
  sMasterConfig.MasterSlaveMode = TIM_MASTERSLAVEMODE_DISABLE;
  if (HAL_TIMEx_MasterConfigSynchronization(&htim6, &sMasterConfig) != HAL_OK)
  {
    _Error_Handler(__FILE__, __LINE__);
  }

}

/* TIM7 init function */
static void MX_TIM7_Init(void)
{

  TIM_MasterConfigTypeDef sMasterConfig;

  htim7.Instance = TIM7;
  htim7.Init.Prescaler = 2-1;
  htim7.Init.CounterMode = TIM_COUNTERMODE_UP;
  htim7.Init.Period = 128
		  ;
  htim7.Init.AutoReloadPreload = TIM_AUTORELOAD_PRELOAD_DISABLE;
  if (HAL_TIM_Base_Init(&htim7) != HAL_OK)
  {
    _Error_Handler(__FILE__, __LINE__);
  }

  sMasterConfig.MasterOutputTrigger = TIM_TRGO_RESET;
  sMasterConfig.MasterSlaveMode = TIM_MASTERSLAVEMODE_DISABLE;
  if (HAL_TIMEx_MasterConfigSynchronization(&htim7, &sMasterConfig) != HAL_OK)
  {
    _Error_Handler(__FILE__, __LINE__);
  }

}

/* TIM8 init function */
static void MX_TIM8_Init(void)
{

  TIM_ClockConfigTypeDef sClockSourceConfig;
  TIM_MasterConfigTypeDef sMasterConfig;

  htim8.Instance = TIM8;
  htim8.Init.Prescaler = 2-1;
  htim8.Init.CounterMode = TIM_COUNTERMODE_UP;
  htim8.Init.Period = 128;
  htim8.Init.ClockDivision = TIM_CLOCKDIVISION_DIV1;
  htim8.Init.RepetitionCounter = 0;
  htim8.Init.AutoReloadPreload = TIM_AUTORELOAD_PRELOAD_DISABLE;
  if (HAL_TIM_Base_Init(&htim8) != HAL_OK)
  {
    _Error_Handler(__FILE__, __LINE__);
  }

  sClockSourceConfig.ClockSource = TIM_CLOCKSOURCE_INTERNAL;
  if (HAL_TIM_ConfigClockSource(&htim8, &sClockSourceConfig) != HAL_OK)
  {
    _Error_Handler(__FILE__, __LINE__);
  }

  sMasterConfig.MasterOutputTrigger = TIM_TRGO_UPDATE;
  sMasterConfig.MasterOutputTrigger2 = TIM_TRGO2_RESET;
  sMasterConfig.MasterSlaveMode = TIM_MASTERSLAVEMODE_DISABLE;
  if (HAL_TIMEx_MasterConfigSynchronization(&htim8, &sMasterConfig) != HAL_OK)
  {
    _Error_Handler(__FILE__, __LINE__);
  }

}

/* TSC init function */
static void MX_TSC_Init(void)
{

    /**Configure the TSC peripheral
    */
  htsc.Instance = TSC;
  htsc.Init.CTPulseHighLength = TSC_CTPH_2CYCLES;
  htsc.Init.CTPulseLowLength = TSC_CTPL_9CYCLES;
  htsc.Init.SpreadSpectrum = DISABLE;
  htsc.Init.SpreadSpectrumDeviation = 1;
  htsc.Init.SpreadSpectrumPrescaler = TSC_SS_PRESC_DIV1;
  htsc.Init.PulseGeneratorPrescaler = TSC_PG_PRESC_DIV32;
  htsc.Init.MaxCountValue = TSC_MCV_16383;
  htsc.Init.IODefaultMode = TSC_IODEF_OUT_PP_LOW;
  htsc.Init.SynchroPinPolarity = TSC_SYNC_POLARITY_FALLING;
  htsc.Init.AcquisitionMode = TSC_ACQ_MODE_NORMAL;
  htsc.Init.MaxCountInterrupt = DISABLE;
  htsc.Init.ChannelIOs = TSC_GROUP5_IO1|TSC_GROUP5_IO2|TSC_GROUP5_IO3|TSC_GROUP6_IO2
                    |TSC_GROUP6_IO3|TSC_GROUP6_IO4;
  htsc.Init.ShieldIOs = TSC_GROUP3_IO4;
  htsc.Init.SamplingIOs = TSC_GROUP3_IO3|TSC_GROUP5_IO4|TSC_GROUP6_IO1;
  if (HAL_TSC_Init(&htsc) != HAL_OK)
  {
    _Error_Handler(__FILE__, __LINE__);
  }

}

static void MX_DMA_Init(void)
{
  /* DMA controller clock enable */
  __HAL_RCC_DMA1_CLK_ENABLE();
  __HAL_RCC_DMA2_CLK_ENABLE();

  /* DMA interrupt init */
  /* DMA1_Channel1_IRQn interrupt configuration */
  HAL_NVIC_SetPriority(DMA1_Channel1_IRQn, 2, 1);
  HAL_NVIC_EnableIRQ(DMA1_Channel1_IRQn);
  /* DMA1_Channel3_IRQn interrupt configuration */
  HAL_NVIC_SetPriority(DMA1_Channel3_IRQn, 0, 0);
  HAL_NVIC_EnableIRQ(DMA1_Channel3_IRQn);
  /* DMA1_Channel4_IRQn interrupt configuration */
  HAL_NVIC_SetPriority(DMA1_Channel4_IRQn, 0, 0);
  HAL_NVIC_EnableIRQ(DMA1_Channel4_IRQn);
  /* DMA2_Channel1_IRQn interrupt configuration */
  HAL_NVIC_SetPriority(DMA2_Channel1_IRQn, 3, 0);
  HAL_NVIC_EnableIRQ(DMA2_Channel1_IRQn);
  /* DMA2_Channel5_IRQn interrupt configuration */
  HAL_NVIC_SetPriority(DMA2_Channel5_IRQn, 2, 0);
  HAL_NVIC_EnableIRQ(DMA2_Channel5_IRQn);

}

/** Configure pins as
        * Analog
        * Input
        * Output
        * EVENT_OUT
        * EXTI
*/
static void MX_GPIO_Init(void)
{

  GPIO_InitTypeDef GPIO_InitStruct;

  /* GPIO Ports Clock Enable */
  __HAL_RCC_GPIOC_CLK_ENABLE();
  __HAL_RCC_GPIOF_CLK_ENABLE();
  __HAL_RCC_GPIOA_CLK_ENABLE();
  __HAL_RCC_GPIOB_CLK_ENABLE();

  /*Configure GPIO pin Output Level */
  HAL_GPIO_WritePin(GPIOC, EOA_Pin|ATTACK_GATE_Pin|EOR_Pin, GPIO_PIN_RESET);

  /*Configure GPIO pin Output Level */
  HAL_GPIO_WritePin(GPIOF, RELEASE_GATE_Pin|A_LED_Pin, GPIO_PIN_RESET);

  /*Configure GPIO pin Output Level */
  HAL_GPIO_WritePin(GPIOB, C_LED_Pin|D_LED_Pin|B_LED_Pin|S_H_A_Pin
                          |S_H_B_Pin, GPIO_PIN_RESET);

  /*Configure GPIO pins : EOA_Pin ATTACK_GATE_Pin EOR_Pin */
  GPIO_InitStruct.Pin = EOA_Pin|ATTACK_GATE_Pin|EOR_Pin;
  GPIO_InitStruct.Mode = GPIO_MODE_OUTPUT_PP;
  GPIO_InitStruct.Pull = GPIO_NOPULL;
  GPIO_InitStruct.Speed = GPIO_SPEED_FREQ_LOW;
  HAL_GPIO_Init(GPIOC, &GPIO_InitStruct);

  /*Configure GPIO pins : RELEASE_GATE_Pin A_LED_Pin */
  GPIO_InitStruct.Pin = RELEASE_GATE_Pin|A_LED_Pin;
  GPIO_InitStruct.Mode = GPIO_MODE_OUTPUT_PP;
  GPIO_InitStruct.Pull = GPIO_NOPULL;
  GPIO_InitStruct.Speed = GPIO_SPEED_FREQ_LOW;
  HAL_GPIO_Init(GPIOF, &GPIO_InitStruct);

  /*Configure GPIO pins : C_LED_Pin D_LED_Pin B_LED_Pin S_H_A_Pin
                           S_H_B_Pin */
  GPIO_InitStruct.Pin = C_LED_Pin|D_LED_Pin|B_LED_Pin|S_H_A_Pin
                          |S_H_B_Pin;
  GPIO_InitStruct.Mode = GPIO_MODE_OUTPUT_PP;
  GPIO_InitStruct.Pull = GPIO_NOPULL;
  GPIO_InitStruct.Speed = GPIO_SPEED_FREQ_LOW;
  HAL_GPIO_Init(GPIOB, &GPIO_InitStruct);

  /*Configure GPIO pin : PA12 */
  GPIO_InitStruct.Pin = GPIO_PIN_12;
  GPIO_InitStruct.Mode = GPIO_MODE_IT_RISING;
  GPIO_InitStruct.Pull = GPIO_NOPULL;
  HAL_GPIO_Init(GPIOA, &GPIO_InitStruct);

  /* EXTI interrupt init*/
  HAL_NVIC_SetPriority(EXTI15_10_IRQn, 1, 0);
  HAL_NVIC_EnableIRQ(EXTI15_10_IRQn);

}

/* USER CODE BEGIN 4 */

void readDetect(void){

	    if (MyTKeys[3].p_Data->StateId == TSL_STATEID_DETECT) {
	    	modeflag = 1;
	    	detectOn = 1;
			clearLEDs();
	    	__HAL_TIM_SET_COUNTER(&htim4, 0);
	    	showMode(scaleMode);
	    }
	    if (MyTKeys[2].p_Data->StateId == TSL_STATEID_DETECT) {
	    	modeflag = 2;
	    	detectOn = 1;
			clearLEDs();
	    	__HAL_TIM_SET_COUNTER(&htim4, 0);
	    	showMode(phaseLockMode);
	    }
	    if (MyTKeys[1].p_Data->StateId == TSL_STATEID_DETECT) {
	    	modeflag = 3;
	    	detectOn = 1;
			clearLEDs();
	    	__HAL_TIM_SET_COUNTER(&htim4, 0);
	    	showMode(controlMode);
	    }
	    if (MyTKeys[4].p_Data->StateId == TSL_STATEID_DETECT) {
	    	modeflag = 4;
	    	detectOn = 1;
			clearLEDs();
	    	__HAL_TIM_SET_COUNTER(&htim4, 0);
	    	showMode(sampleHoldMode);
	    }
	    if (MyTKeys[5].p_Data->StateId == TSL_STATEID_DETECT) {
	    	modeflag = 5;
	    	detectOn = 1;
			clearLEDs();
	    	__HAL_TIM_SET_COUNTER(&htim4, 0);
	    	showMode(familyIndicator);
	    }
	    if (MyTKeys[0].p_Data->StateId == TSL_STATEID_DETECT) {
	    	modeflag = 6;
	    	detectOn = 1;
			clearLEDs();
	    	__HAL_TIM_SET_COUNTER(&htim4, 0);
	    	showMode(familyIndicator);
	    }

}

void readRelease(uint8_t modeFlagHolder ) {

	switch (modeFlagHolder) {

	case 1 :

	    if (MyTKeys[3].p_Data->StateId == TSL_STATEID_RELEASE) {
	    	detectOn = 0;
			clearLEDs();
	    	handleRelease(modeFlagHolder);
	    }
	    break;

	case 2 :

	    if (MyTKeys[2].p_Data->StateId == TSL_STATEID_RELEASE) {
	    	detectOn = 0;
			clearLEDs();
	    	handleRelease(modeFlagHolder);
	    }
	    break;

	case 3 :

	    if (MyTKeys[1].p_Data->StateId == TSL_STATEID_RELEASE) {
	    	detectOn = 0;
			clearLEDs();
	    	handleRelease(modeFlagHolder);
	    }
	    break;

	case 4 :

	    if (MyTKeys[4].p_Data->StateId == TSL_STATEID_RELEASE) {
	    	detectOn = 0;
			clearLEDs();
	    	handleRelease(modeFlagHolder);
	    }
	    break;

	case 5 :

	    if (MyTKeys[5].p_Data->StateId == TSL_STATEID_RELEASE) {
	    	detectOn = 0;
			clearLEDs();
	    	handleRelease(modeFlagHolder);
	    }
	    break;

	case 6 :

	    if (MyTKeys[0].p_Data->StateId == TSL_STATEID_RELEASE) {
	    	detectOn = 0;
			clearLEDs();
	    	handleRelease(modeFlagHolder);
	    }
	    break;

	}

}

void handleRelease(uint8_t pinMode) {
	if (__HAL_TIM_GET_COUNTER(&htim4) < 10000) {
		changeMode(pinMode);
		switch (pinMode) {
		case 1: showMode(scaleMode);
				break;
		case 2: showMode(phaseLockMode);
				break;
		case 3: showMode(controlMode);
				break;
		case 4: showMode(sampleHoldMode);
				break;
		case 5: showMode(familyIndicator);
				break;
		case 6: showMode(familyIndicator);
				break;
		}
		displayNewMode = 1;
		__HAL_TIM_SET_COUNTER(&htim4, 0);
	}
	else {
		clearLEDs();
		rgbOn = 1;
	}
}

void changeMode(uint8_t mode) {
		if (mode == 1) {
			scaleMode = (scaleMode + 1) % 2;
		}
		if (mode == 2) {
			controlMode = (controlMode + 1) % 2;
		}
		if (mode == 3) {
			phaseLockMode = (phaseLockMode + 1) % 4;
		}
		if (mode == 4) {
			sampleHoldMode = (sampleHoldMode + 1) % 6;
		}
		if (mode == 5) {
			familyIndicator = (familyIndicator + 1) % 15;
			span = (familyArray[familyIndicator].tableLength) << 16;
			spanx2 = (familyArray[familyIndicator].tableLength) << 17;
			switch (familyArray[familyIndicator].familySize) {

								case 5:
									morphBitShiftRight = 10;
									morphBitShiftLeft = 6;
									break;

								case 9:
									morphBitShiftRight = 9;
									morphBitShiftLeft = 7;
									break;

								case 17:
									morphBitShiftRight = 8;
									morphBitShiftLeft = 8;
									break;

								case 33:
									morphBitShiftRight = 7;
									morphBitShiftLeft = 9;
									break;

							}
		}
		if (mode == 6) {
			if (familyIndicator == 0) {familyIndicator = 14;}
			else familyIndicator = (familyIndicator - 1);
			span = (familyArray[familyIndicator].tableLength) << 16;
			spanx2 = (familyArray[familyIndicator].tableLength) << 17;
			switch (familyArray[familyIndicator].familySize) {

					case 5:
						morphBitShiftRight = 10;
						morphBitShiftLeft = 6;
						break;

					case 9:
						morphBitShiftRight = 9;
						morphBitShiftLeft = 7;
						break;

					case 17:
						morphBitShiftRight = 8;
						morphBitShiftLeft = 8;
						break;

					case 33:
						morphBitShiftRight = 7;
						morphBitShiftLeft = 9;
						break;

				}
			}
		}

void showMode(uint8_t currentmode) {
	if (currentmode == familyIndicator) {familyRGB();}

	else {
		switch (currentmode) {

			case 0 :
				LEDA_ON
				break;
			case 1 :
				LEDB_ON
				break;
			case 2 :
				LEDC_ON
				break;
			case 3 :
				LEDD_ON
				break;
			case 4 :
				LEDA_ON
				LEDB_ON
				break;
			case 5 :
				LEDC_ON
				LEDD_ON
				break;
		}
	}

}

void familyRGB(void) {
	__HAL_TIM_SET_COMPARE(&htim1, TIM_CHANNEL_1, familyIndicator << 8);
	__HAL_TIM_SET_COMPARE(&htim1, TIM_CHANNEL_2, familyIndicator << 4);
	__HAL_TIM_SET_COMPARE(&htim1, TIM_CHANNEL_3, 4095 - (familyIndicator << 8));
}
void clearLEDs(void) {
	HAL_GPIO_WritePin(GPIOF, GPIO_PIN_1, GPIO_PIN_RESET);
	HAL_GPIO_WritePin(GPIOB, GPIO_PIN_5, GPIO_PIN_RESET);
	HAL_GPIO_WritePin(GPIOB, GPIO_PIN_10, GPIO_PIN_RESET);
	HAL_GPIO_WritePin(GPIOB, GPIO_PIN_15, GPIO_PIN_RESET);
}

void restoreDisplay() {
	if (__HAL_TIM_GET_COUNTER(&htim4) > 5000) {
		clearLEDs();
		rgbOn = 1;
		displayNewMode = 0;
	}
}

/* USER CODE END 4 */

void _Error_Handler(char * file, int line)
{
  while(1)
  {
  }
}

/************************ (C) COPYRIGHT STMicroelectronics *****END OF FILE****/
